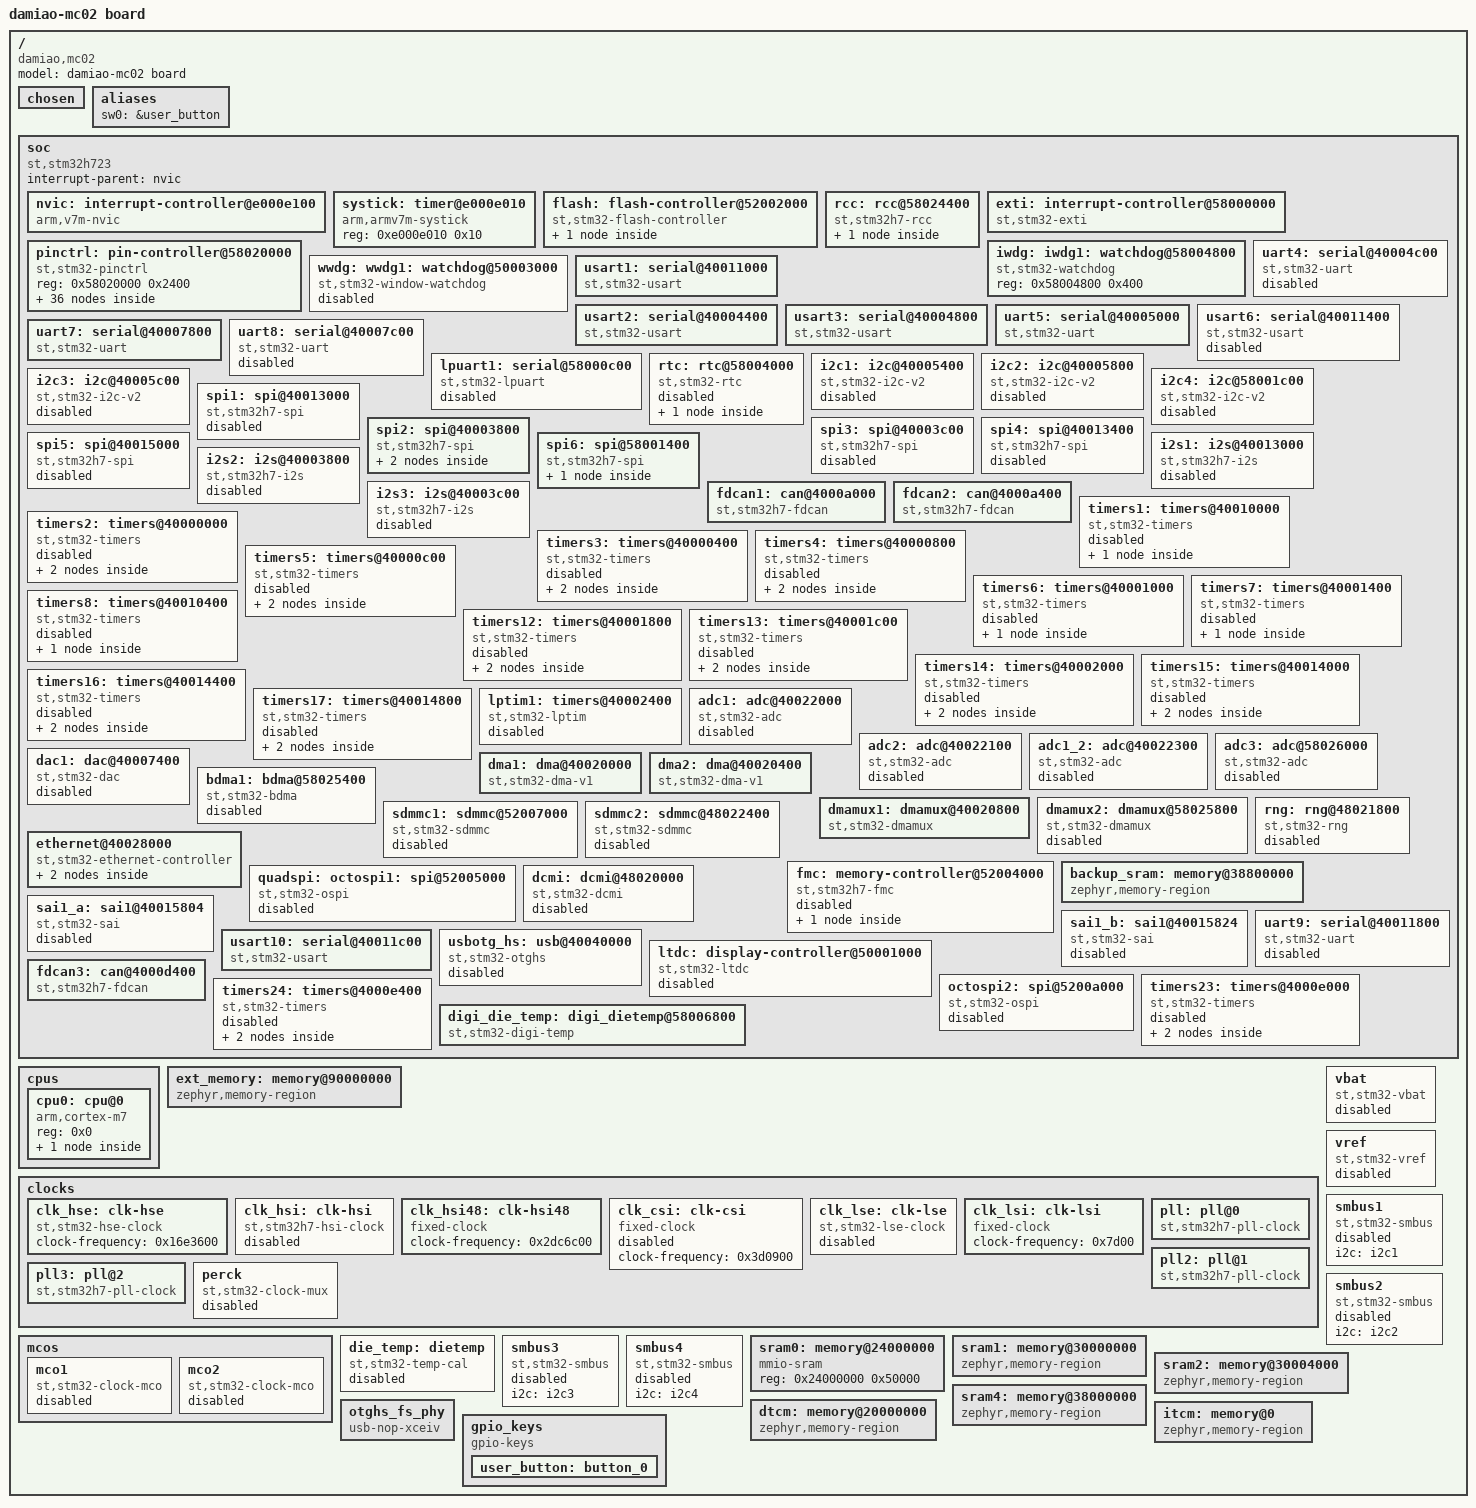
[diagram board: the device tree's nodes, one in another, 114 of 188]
/dts-v1/;

/* node '/' defined in Engineer-sdk/zephyr/dts/common/skeleton.dtsi:9 */
/ {
	#address-cells = < 0x1 >;    /* in Engineer-sdk/zephyr/dts/common/skeleton.dtsi:10 */
	#size-cells = < 0x1 >;       /* in Engineer-sdk/zephyr/dts/common/skeleton.dtsi:11 */
	model = "damiao-mc02 board"; /* in Engineer-manifest/boards/damiao/mc02/damiao_mc02.dts:24 */
	compatible = "damiao,mc02",
	             "st,stm32h723"; /* in Engineer-manifest/boards/damiao/mc02/damiao_mc02.dts:25 */

	/* node '/chosen' defined in Engineer-sdk/zephyr/dts/common/skeleton.dtsi:12 */
	chosen {
		zephyr,entropy = &rng;            /* in Engineer-sdk/zephyr/dts/arm/st/h7/stm32h7.dtsi:28 */
		zephyr,flash-controller = &flash; /* in Engineer-sdk/zephyr/dts/arm/st/h7/stm32h7.dtsi:29 */
		zephyr,dtcm = &dtcm;              /* in Engineer-manifest/boards/damiao/mc02/damiao_mc02.dts:28 */
		zephyr,sram = &sram0;             /* in Engineer-manifest/boards/damiao/mc02/damiao_mc02.dts:29 */
		zephyr,itcm = &itcm;              /* in Engineer-manifest/boards/damiao/mc02/damiao_mc02.dts:30 */
		zephyr,flash = &flash0;           /* in Engineer-manifest/boards/damiao/mc02/damiao_mc02.dts:31 */
	};

	/* node '/aliases' defined in Engineer-sdk/zephyr/dts/common/skeleton.dtsi:13 */
	aliases {
		sw0 = &user_button; /* in Engineer-manifest/boards/damiao/mc02/damiao_mc02.dts:44 */
	};

	/* node '/soc' defined in Engineer-sdk/zephyr/dts/arm/armv7-m.dtsi:6 */
	soc {
		#address-cells = < 0x1 >;     /* in Engineer-sdk/zephyr/dts/arm/armv7-m.dtsi:7 */
		#size-cells = < 0x1 >;        /* in Engineer-sdk/zephyr/dts/arm/armv7-m.dtsi:8 */
		interrupt-parent = < &nvic >; /* in Engineer-sdk/zephyr/dts/arm/armv7-m.dtsi:10 */
		ranges;                       /* in Engineer-sdk/zephyr/dts/arm/armv7-m.dtsi:11 */
		compatible = "st,stm32h723",
		             "st,stm32h7",
		             "simple-bus";    /* in Engineer-sdk/zephyr/dts/arm/st/h7/stm32h723.dtsi:15 */

		/* node '/soc/interrupt-controller@e000e100' defined in Engineer-sdk/zephyr/dts/arm/armv7-m.dtsi:13 */
		nvic: interrupt-controller@e000e100 {
			#address-cells = < 0x1 >;            /* in Engineer-sdk/zephyr/dts/arm/armv7-m.dtsi:14 */
			compatible = "arm,v7m-nvic";         /* in Engineer-sdk/zephyr/dts/arm/armv7-m.dtsi:15 */
			reg = < 0xe000e100 0xc00 >;          /* in Engineer-sdk/zephyr/dts/arm/armv7-m.dtsi:16 */
			interrupt-controller;                /* in Engineer-sdk/zephyr/dts/arm/armv7-m.dtsi:17 */
			#interrupt-cells = < 0x2 >;          /* in Engineer-sdk/zephyr/dts/arm/armv7-m.dtsi:18 */
			arm,num-irq-priority-bits = < 0x4 >; /* in Engineer-sdk/zephyr/dts/arm/st/h7/stm32h7.dtsi:1196 */
			phandle = < 0x1 >;                   /* in Engineer-sdk/zephyr/dts/arm/armv7-m.dtsi:10 */
		};

		/* node '/soc/timer@e000e010' defined in Engineer-sdk/zephyr/dts/arm/armv7-m.dtsi:21 */
		systick: timer@e000e010 {
			compatible = "arm,armv7m-systick"; /* in Engineer-sdk/zephyr/dts/arm/armv7-m.dtsi:22 */
			reg = < 0xe000e010 0x10 >;         /* in Engineer-sdk/zephyr/dts/arm/armv7-m.dtsi:23 */
		};

		/* node '/soc/flash-controller@52002000' defined in Engineer-sdk/zephyr/dts/arm/st/h7/stm32h7.dtsi:145 */
		flash: flash-controller@52002000 {
			compatible = "st,stm32-flash-controller",
			             "st,stm32h7-flash-controller"; /* in Engineer-sdk/zephyr/dts/arm/st/h7/stm32h7.dtsi:146 */
			reg = < 0x52002000 0x400 >;                 /* in Engineer-sdk/zephyr/dts/arm/st/h7/stm32h7.dtsi:147 */
			interrupts = < 0x4 0x0 >;                   /* in Engineer-sdk/zephyr/dts/arm/st/h7/stm32h7.dtsi:148 */
			#address-cells = < 0x1 >;                   /* in Engineer-sdk/zephyr/dts/arm/st/h7/stm32h7.dtsi:150 */
			#size-cells = < 0x1 >;                      /* in Engineer-sdk/zephyr/dts/arm/st/h7/stm32h7.dtsi:151 */

			/* node '/soc/flash-controller@52002000/flash@8000000' defined in Engineer-sdk/zephyr/dts/arm/st/h7/stm32h723.dtsi:18 */
			flash0: flash@8000000 {
				compatible = "st,stm32-nv-flash",
				             "soc-nv-flash";      /* in Engineer-sdk/zephyr/dts/arm/st/h7/stm32h723.dtsi:19 */
				write-block-size = < 0x20 >;      /* in Engineer-sdk/zephyr/dts/arm/st/h7/stm32h723.dtsi:20 */
				erase-block-size = < 0x20000 >;   /* in Engineer-sdk/zephyr/dts/arm/st/h7/stm32h723.dtsi:21 */
				max-erase-time = < 0xfa0 >;       /* in Engineer-sdk/zephyr/dts/arm/st/h7/stm32h723.dtsi:23 */
				reg = < 0x8000000 0x100000 >;     /* in Engineer-sdk/zephyr/dts/arm/st/h7/stm32h723Xg.dtsi:14 */
			};
		};

		/* node '/soc/rcc@58024400' defined in Engineer-sdk/zephyr/dts/arm/st/h7/stm32h7.dtsi:154 */
		rcc: rcc@58024400 {
			compatible = "st,stm32h7-rcc";    /* in Engineer-sdk/zephyr/dts/arm/st/h7/stm32h7.dtsi:155 */
			#clock-cells = < 0x2 >;           /* in Engineer-sdk/zephyr/dts/arm/st/h7/stm32h7.dtsi:156 */
			reg = < 0x58024400 0x400 >;       /* in Engineer-sdk/zephyr/dts/arm/st/h7/stm32h7.dtsi:157 */
			clocks = < &pll >;                /* in Engineer-manifest/boards/damiao/mc02/damiao_mc02.dts:96 */
			clock-frequency = < 0x20c85580 >; /* in Engineer-manifest/boards/damiao/mc02/damiao_mc02.dts:97 */
			d1cpre = < 0x1 >;                 /* in Engineer-manifest/boards/damiao/mc02/damiao_mc02.dts:98 */
			hpre = < 0x2 >;                   /* in Engineer-manifest/boards/damiao/mc02/damiao_mc02.dts:99 */
			d1ppre = < 0x2 >;                 /* in Engineer-manifest/boards/damiao/mc02/damiao_mc02.dts:100 */
			d2ppre1 = < 0x2 >;                /* in Engineer-manifest/boards/damiao/mc02/damiao_mc02.dts:101 */
			d2ppre2 = < 0x2 >;                /* in Engineer-manifest/boards/damiao/mc02/damiao_mc02.dts:102 */
			d3ppre = < 0x2 >;                 /* in Engineer-manifest/boards/damiao/mc02/damiao_mc02.dts:103 */
			phandle = < 0x3 >;                /* in Engineer-sdk/zephyr/dts/arm/st/h7/stm32h7.dtsi:171 */

			/* node '/soc/rcc@58024400/reset-controller' defined in Engineer-sdk/zephyr/dts/arm/st/h7/stm32h7.dtsi:159 */
			rctl: reset-controller {
				compatible = "st,stm32-rcc-rctl"; /* in Engineer-sdk/zephyr/dts/arm/st/h7/stm32h7.dtsi:160 */
				#reset-cells = < 0x1 >;           /* in Engineer-sdk/zephyr/dts/arm/st/h7/stm32h7.dtsi:161 */
				phandle = < 0x4 >;                /* in Engineer-sdk/zephyr/dts/arm/st/h7/stm32h7.dtsi:294 */
			};
		};

		/* node '/soc/interrupt-controller@58000000' defined in Engineer-sdk/zephyr/dts/arm/st/h7/stm32h7.dtsi:165 */
		exti: interrupt-controller@58000000 {
			compatible = "st,stm32-exti";  /* in Engineer-sdk/zephyr/dts/arm/st/h7/stm32h7.dtsi:166 */
			interrupt-controller;          /* in Engineer-sdk/zephyr/dts/arm/st/h7/stm32h7.dtsi:167 */
			#interrupt-cells = < 0x1 >;    /* in Engineer-sdk/zephyr/dts/arm/st/h7/stm32h7.dtsi:168 */
			#address-cells = < 0x1 >;      /* in Engineer-sdk/zephyr/dts/arm/st/h7/stm32h7.dtsi:169 */
			reg = < 0x58000000 0x400 >;    /* in Engineer-sdk/zephyr/dts/arm/st/h7/stm32h7.dtsi:170 */
			clocks = < &rcc 0xf4 0x2 >;    /* in Engineer-sdk/zephyr/dts/arm/st/h7/stm32h7.dtsi:171 */
			num-lines = < 0x60 >;          /* in Engineer-sdk/zephyr/dts/arm/st/h7/stm32h7.dtsi:172 */
			interrupts = < 0x6 0x0 >,
			             < 0x7 0x0 >,
			             < 0x8 0x0 >,
			             < 0x9 0x0 >,
			             < 0xa 0x0 >,
			             < 0x17 0x0 >,
			             < 0x28 0x0 >;     /* in Engineer-sdk/zephyr/dts/arm/st/h7/stm32h7.dtsi:173 */
			interrupt-names = "line0",
			                  "line1",
			                  "line2",
			                  "line3",
			                  "line4",
			                  "line5-9",
			                  "line10-15"; /* in Engineer-sdk/zephyr/dts/arm/st/h7/stm32h7.dtsi:175 */
			line-ranges = < 0x0 0x1 >,
			              < 0x1 0x1 >,
			              < 0x2 0x1 >,
			              < 0x3 0x1 >,
			              < 0x4 0x1 >,
			              < 0x5 0x5 >,
			              < 0xa 0x6 >;     /* in Engineer-sdk/zephyr/dts/arm/st/h7/stm32h7.dtsi:177 */
		};

		/* node '/soc/pin-controller@58020000' defined in Engineer-sdk/zephyr/dts/arm/st/h7/stm32h7.dtsi:181 */
		pinctrl: pin-controller@58020000 {
			compatible = "st,stm32-pinctrl"; /* in Engineer-sdk/zephyr/dts/arm/st/h7/stm32h7.dtsi:182 */
			#address-cells = < 0x1 >;        /* in Engineer-sdk/zephyr/dts/arm/st/h7/stm32h7.dtsi:183 */
			#size-cells = < 0x1 >;           /* in Engineer-sdk/zephyr/dts/arm/st/h7/stm32h7.dtsi:184 */
			reg = < 0x58020000 0x2400 >;     /* in Engineer-sdk/zephyr/dts/arm/st/h7/stm32h7.dtsi:185 */

			/* node '/soc/pin-controller@58020000/gpio@58020000' defined in Engineer-sdk/zephyr/dts/arm/st/h7/stm32h7.dtsi:187 */
			gpioa: gpio@58020000 {
				compatible = "st,stm32-gpio"; /* in Engineer-sdk/zephyr/dts/arm/st/h7/stm32h7.dtsi:188 */
				gpio-controller;              /* in Engineer-sdk/zephyr/dts/arm/st/h7/stm32h7.dtsi:189 */
				#gpio-cells = < 0x2 >;        /* in Engineer-sdk/zephyr/dts/arm/st/h7/stm32h7.dtsi:190 */
				reg = < 0x58020000 0x400 >;   /* in Engineer-sdk/zephyr/dts/arm/st/h7/stm32h7.dtsi:191 */
				clocks = < &rcc 0xe0 0x1 >;   /* in Engineer-sdk/zephyr/dts/arm/st/h7/stm32h7.dtsi:192 */
				phandle = < 0x2a >;           /* in Engineer-manifest/boards/damiao/mc02/damiao_mc02.dts:37 */
			};

			/* node '/soc/pin-controller@58020000/gpio@58020400' defined in Engineer-sdk/zephyr/dts/arm/st/h7/stm32h7.dtsi:195 */
			gpiob: gpio@58020400 {
				compatible = "st,stm32-gpio"; /* in Engineer-sdk/zephyr/dts/arm/st/h7/stm32h7.dtsi:196 */
				gpio-controller;              /* in Engineer-sdk/zephyr/dts/arm/st/h7/stm32h7.dtsi:197 */
				#gpio-cells = < 0x2 >;        /* in Engineer-sdk/zephyr/dts/arm/st/h7/stm32h7.dtsi:198 */
				reg = < 0x58020400 0x400 >;   /* in Engineer-sdk/zephyr/dts/arm/st/h7/stm32h7.dtsi:199 */
				clocks = < &rcc 0xe0 0x2 >;   /* in Engineer-sdk/zephyr/dts/arm/st/h7/stm32h7.dtsi:200 */
			};

			/* node '/soc/pin-controller@58020000/gpio@58020800' defined in Engineer-sdk/zephyr/dts/arm/st/h7/stm32h7.dtsi:203 */
			gpioc: gpio@58020800 {
				compatible = "st,stm32-gpio"; /* in Engineer-sdk/zephyr/dts/arm/st/h7/stm32h7.dtsi:204 */
				gpio-controller;              /* in Engineer-sdk/zephyr/dts/arm/st/h7/stm32h7.dtsi:205 */
				#gpio-cells = < 0x2 >;        /* in Engineer-sdk/zephyr/dts/arm/st/h7/stm32h7.dtsi:206 */
				reg = < 0x58020800 0x400 >;   /* in Engineer-sdk/zephyr/dts/arm/st/h7/stm32h7.dtsi:207 */
				clocks = < &rcc 0xe0 0x4 >;   /* in Engineer-sdk/zephyr/dts/arm/st/h7/stm32h7.dtsi:208 */
				phandle = < 0x15 >;           /* in Engineer-manifest/boards/damiao/mc02/damiao_mc02.dts:148 */
			};

			/* node '/soc/pin-controller@58020000/gpio@58020C00' defined in Engineer-sdk/zephyr/dts/arm/st/h7/stm32h7.dtsi:211 */
			gpiod: gpio@58020C00 {
				compatible = "st,stm32-gpio"; /* in Engineer-sdk/zephyr/dts/arm/st/h7/stm32h7.dtsi:212 */
				gpio-controller;              /* in Engineer-sdk/zephyr/dts/arm/st/h7/stm32h7.dtsi:213 */
				#gpio-cells = < 0x2 >;        /* in Engineer-sdk/zephyr/dts/arm/st/h7/stm32h7.dtsi:214 */
				reg = < 0x58020c00 0x400 >;   /* in Engineer-sdk/zephyr/dts/arm/st/h7/stm32h7.dtsi:215 */
				clocks = < &rcc 0xe0 0x8 >;   /* in Engineer-sdk/zephyr/dts/arm/st/h7/stm32h7.dtsi:216 */
			};

			/* node '/soc/pin-controller@58020000/gpio@58021000' defined in Engineer-sdk/zephyr/dts/arm/st/h7/stm32h7.dtsi:219 */
			gpioe: gpio@58021000 {
				compatible = "st,stm32-gpio"; /* in Engineer-sdk/zephyr/dts/arm/st/h7/stm32h7.dtsi:220 */
				gpio-controller;              /* in Engineer-sdk/zephyr/dts/arm/st/h7/stm32h7.dtsi:221 */
				#gpio-cells = < 0x2 >;        /* in Engineer-sdk/zephyr/dts/arm/st/h7/stm32h7.dtsi:222 */
				reg = < 0x58021000 0x400 >;   /* in Engineer-sdk/zephyr/dts/arm/st/h7/stm32h7.dtsi:223 */
				clocks = < &rcc 0xe0 0x10 >;  /* in Engineer-sdk/zephyr/dts/arm/st/h7/stm32h7.dtsi:224 */
				phandle = < 0x16 >;           /* in Engineer-manifest/boards/damiao/mc02/damiao_mc02.dts:160 */
			};

			/* node '/soc/pin-controller@58020000/gpio@58021400' defined in Engineer-sdk/zephyr/dts/arm/st/h7/stm32h7.dtsi:227 */
			gpiof: gpio@58021400 {
				compatible = "st,stm32-gpio"; /* in Engineer-sdk/zephyr/dts/arm/st/h7/stm32h7.dtsi:228 */
				gpio-controller;              /* in Engineer-sdk/zephyr/dts/arm/st/h7/stm32h7.dtsi:229 */
				#gpio-cells = < 0x2 >;        /* in Engineer-sdk/zephyr/dts/arm/st/h7/stm32h7.dtsi:230 */
				reg = < 0x58021400 0x400 >;   /* in Engineer-sdk/zephyr/dts/arm/st/h7/stm32h7.dtsi:231 */
				clocks = < &rcc 0xe0 0x20 >;  /* in Engineer-sdk/zephyr/dts/arm/st/h7/stm32h7.dtsi:232 */
			};

			/* node '/soc/pin-controller@58020000/gpio@58021800' defined in Engineer-sdk/zephyr/dts/arm/st/h7/stm32h7.dtsi:235 */
			gpiog: gpio@58021800 {
				compatible = "st,stm32-gpio"; /* in Engineer-sdk/zephyr/dts/arm/st/h7/stm32h7.dtsi:236 */
				gpio-controller;              /* in Engineer-sdk/zephyr/dts/arm/st/h7/stm32h7.dtsi:237 */
				#gpio-cells = < 0x2 >;        /* in Engineer-sdk/zephyr/dts/arm/st/h7/stm32h7.dtsi:238 */
				reg = < 0x58021800 0x400 >;   /* in Engineer-sdk/zephyr/dts/arm/st/h7/stm32h7.dtsi:239 */
				clocks = < &rcc 0xe0 0x40 >;  /* in Engineer-sdk/zephyr/dts/arm/st/h7/stm32h7.dtsi:240 */
			};

			/* node '/soc/pin-controller@58020000/gpio@58021C00' defined in Engineer-sdk/zephyr/dts/arm/st/h7/stm32h7.dtsi:243 */
			gpioh: gpio@58021C00 {
				compatible = "st,stm32-gpio"; /* in Engineer-sdk/zephyr/dts/arm/st/h7/stm32h7.dtsi:244 */
				gpio-controller;              /* in Engineer-sdk/zephyr/dts/arm/st/h7/stm32h7.dtsi:245 */
				#gpio-cells = < 0x2 >;        /* in Engineer-sdk/zephyr/dts/arm/st/h7/stm32h7.dtsi:246 */
				reg = < 0x58021c00 0x400 >;   /* in Engineer-sdk/zephyr/dts/arm/st/h7/stm32h7.dtsi:247 */
				clocks = < &rcc 0xe0 0x80 >;  /* in Engineer-sdk/zephyr/dts/arm/st/h7/stm32h7.dtsi:248 */
			};

			/* node '/soc/pin-controller@58020000/gpio@58022000' defined in Engineer-sdk/zephyr/dts/arm/st/h7/stm32h7.dtsi:251 */
			gpioi: gpio@58022000 {
				compatible = "st,stm32-gpio"; /* in Engineer-sdk/zephyr/dts/arm/st/h7/stm32h7.dtsi:252 */
				gpio-controller;              /* in Engineer-sdk/zephyr/dts/arm/st/h7/stm32h7.dtsi:253 */
				#gpio-cells = < 0x2 >;        /* in Engineer-sdk/zephyr/dts/arm/st/h7/stm32h7.dtsi:254 */
				reg = < 0x58022000 0x400 >;   /* in Engineer-sdk/zephyr/dts/arm/st/h7/stm32h7.dtsi:255 */
				clocks = < &rcc 0xe0 0x100 >; /* in Engineer-sdk/zephyr/dts/arm/st/h7/stm32h7.dtsi:256 */
			};

			/* node '/soc/pin-controller@58020000/gpio@58022400' defined in Engineer-sdk/zephyr/dts/arm/st/h7/stm32h7.dtsi:259 */
			gpioj: gpio@58022400 {
				compatible = "st,stm32-gpio"; /* in Engineer-sdk/zephyr/dts/arm/st/h7/stm32h7.dtsi:260 */
				gpio-controller;              /* in Engineer-sdk/zephyr/dts/arm/st/h7/stm32h7.dtsi:261 */
				#gpio-cells = < 0x2 >;        /* in Engineer-sdk/zephyr/dts/arm/st/h7/stm32h7.dtsi:262 */
				reg = < 0x58022400 0x400 >;   /* in Engineer-sdk/zephyr/dts/arm/st/h7/stm32h7.dtsi:263 */
				clocks = < &rcc 0xe0 0x200 >; /* in Engineer-sdk/zephyr/dts/arm/st/h7/stm32h7.dtsi:264 */
			};

			/* node '/soc/pin-controller@58020000/gpio@58022800' defined in Engineer-sdk/zephyr/dts/arm/st/h7/stm32h7.dtsi:267 */
			gpiok: gpio@58022800 {
				compatible = "st,stm32-gpio"; /* in Engineer-sdk/zephyr/dts/arm/st/h7/stm32h7.dtsi:268 */
				gpio-controller;              /* in Engineer-sdk/zephyr/dts/arm/st/h7/stm32h7.dtsi:269 */
				#gpio-cells = < 0x2 >;        /* in Engineer-sdk/zephyr/dts/arm/st/h7/stm32h7.dtsi:270 */
				reg = < 0x58022800 0x400 >;   /* in Engineer-sdk/zephyr/dts/arm/st/h7/stm32h7.dtsi:271 */
				clocks = < &rcc 0xe0 0x400 >; /* in Engineer-sdk/zephyr/dts/arm/st/h7/stm32h7.dtsi:272 */
			};

			/* node '/soc/pin-controller@58020000/fdcan1_rx_pd0' defined in Engineer-sdk/modules/hal/stm32/dts/st/h7/stm32h723vgtx-pinctrl.dtsi:1060 */
			fdcan1_rx_pd0: fdcan1_rx_pd0 {
				pinmux = < 0x609 >; /* in Engineer-sdk/modules/hal/stm32/dts/st/h7/stm32h723vgtx-pinctrl.dtsi:1061 */
				phandle = < 0x1a >; /* in Engineer-manifest/boards/damiao/mc02/damiao_mc02.dts:320 */
			};

			/* node '/soc/pin-controller@58020000/fdcan2_rx_pb5' defined in Engineer-sdk/modules/hal/stm32/dts/st/h7/stm32h723vgtx-pinctrl.dtsi:1064 */
			fdcan2_rx_pb5: fdcan2_rx_pb5 {
				pinmux = < 0x2a9 >; /* in Engineer-sdk/modules/hal/stm32/dts/st/h7/stm32h723vgtx-pinctrl.dtsi:1065 */
				phandle = < 0x1c >; /* in Engineer-manifest/boards/damiao/mc02/damiao_mc02.dts:329 */
			};

			/* node '/soc/pin-controller@58020000/fdcan3_rx_pd12' defined in Engineer-sdk/modules/hal/stm32/dts/st/h7/stm32h723vgtx-pinctrl.dtsi:1072 */
			fdcan3_rx_pd12: fdcan3_rx_pd12 {
				pinmux = < 0x785 >; /* in Engineer-sdk/modules/hal/stm32/dts/st/h7/stm32h723vgtx-pinctrl.dtsi:1073 */
				phandle = < 0x22 >; /* in Engineer-manifest/boards/damiao/mc02/damiao_mc02.dts:338 */
			};

			/* node '/soc/pin-controller@58020000/fdcan1_tx_pd1' defined in Engineer-sdk/modules/hal/stm32/dts/st/h7/stm32h723vgtx-pinctrl.dtsi:1086 */
			fdcan1_tx_pd1: fdcan1_tx_pd1 {
				pinmux = < 0x629 >; /* in Engineer-sdk/modules/hal/stm32/dts/st/h7/stm32h723vgtx-pinctrl.dtsi:1087 */
				phandle = < 0x1b >; /* in Engineer-manifest/boards/damiao/mc02/damiao_mc02.dts:320 */
			};

			/* node '/soc/pin-controller@58020000/fdcan2_tx_pb6' defined in Engineer-sdk/modules/hal/stm32/dts/st/h7/stm32h723vgtx-pinctrl.dtsi:1090 */
			fdcan2_tx_pb6: fdcan2_tx_pb6 {
				pinmux = < 0x2c9 >; /* in Engineer-sdk/modules/hal/stm32/dts/st/h7/stm32h723vgtx-pinctrl.dtsi:1091 */
				phandle = < 0x1d >; /* in Engineer-manifest/boards/damiao/mc02/damiao_mc02.dts:329 */
			};

			/* node '/soc/pin-controller@58020000/fdcan3_tx_pd13' defined in Engineer-sdk/modules/hal/stm32/dts/st/h7/stm32h723vgtx-pinctrl.dtsi:1098 */
			fdcan3_tx_pd13: fdcan3_tx_pd13 {
				pinmux = < 0x7a5 >; /* in Engineer-sdk/modules/hal/stm32/dts/st/h7/stm32h723vgtx-pinctrl.dtsi:1099 */
				phandle = < 0x23 >; /* in Engineer-manifest/boards/damiao/mc02/damiao_mc02.dts:338 */
			};

			/* node '/soc/pin-controller@58020000/spi2_miso_pc2_c' defined in Engineer-sdk/modules/hal/stm32/dts/st/h7/stm32h723vgtx-pinctrl.dtsi:2577 */
			spi2_miso_pc2_c: spi2_miso_pc2_c {
				pinmux = < 0x445 >; /* in Engineer-sdk/modules/hal/stm32/dts/st/h7/stm32h723vgtx-pinctrl.dtsi:2578 */
				bias-pull-down;     /* in Engineer-sdk/modules/hal/stm32/dts/st/h7/stm32h723vgtx-pinctrl.dtsi:2579 */
				phandle = < 0x13 >; /* in Engineer-manifest/boards/damiao/mc02/damiao_mc02.dts:146 */
			};

			/* node '/soc/pin-controller@58020000/spi2_mosi_pc1' defined in Engineer-sdk/modules/hal/stm32/dts/st/h7/stm32h723vgtx-pinctrl.dtsi:2634 */
			spi2_mosi_pc1: spi2_mosi_pc1 {
				pinmux = < 0x425 >; /* in Engineer-sdk/modules/hal/stm32/dts/st/h7/stm32h723vgtx-pinctrl.dtsi:2635 */
				bias-pull-down;     /* in Engineer-sdk/modules/hal/stm32/dts/st/h7/stm32h723vgtx-pinctrl.dtsi:2636 */
				phandle = < 0x14 >; /* in Engineer-manifest/boards/damiao/mc02/damiao_mc02.dts:146 */
			};

			/* node '/soc/pin-controller@58020000/spi6_mosi_pa7' defined in Engineer-sdk/modules/hal/stm32/dts/st/h7/stm32h723vgtx-pinctrl.dtsi:2674 */
			spi6_mosi_pa7: spi6_mosi_pa7 {
				pinmux = < 0xe8 >;  /* in Engineer-sdk/modules/hal/stm32/dts/st/h7/stm32h723vgtx-pinctrl.dtsi:2675 */
				bias-pull-down;     /* in Engineer-sdk/modules/hal/stm32/dts/st/h7/stm32h723vgtx-pinctrl.dtsi:2676 */
				phandle = < 0x19 >; /* in Engineer-manifest/boards/damiao/mc02/damiao_mc02.dts:190 */
			};

			/* node '/soc/pin-controller@58020000/spi2_sck_pb13' defined in Engineer-sdk/modules/hal/stm32/dts/st/h7/stm32h723vgtx-pinctrl.dtsi:2783 */
			spi2_sck_pb13: spi2_sck_pb13 {
				pinmux = < 0x3a5 >;            /* in Engineer-sdk/modules/hal/stm32/dts/st/h7/stm32h723vgtx-pinctrl.dtsi:2784 */
				bias-pull-down;                /* in Engineer-sdk/modules/hal/stm32/dts/st/h7/stm32h723vgtx-pinctrl.dtsi:2785 */
				slew-rate = "very-high-speed"; /* in Engineer-sdk/modules/hal/stm32/dts/st/h7/stm32h723vgtx-pinctrl.dtsi:2786 */
				phandle = < 0x12 >;            /* in Engineer-manifest/boards/damiao/mc02/damiao_mc02.dts:146 */
			};

			/* node '/soc/pin-controller@58020000/spi6_sck_pa5' defined in Engineer-sdk/modules/hal/stm32/dts/st/h7/stm32h723vgtx-pinctrl.dtsi:2819 */
			spi6_sck_pa5: spi6_sck_pa5 {
				pinmux = < 0xa8 >;             /* in Engineer-sdk/modules/hal/stm32/dts/st/h7/stm32h723vgtx-pinctrl.dtsi:2820 */
				bias-pull-down;                /* in Engineer-sdk/modules/hal/stm32/dts/st/h7/stm32h723vgtx-pinctrl.dtsi:2821 */
				slew-rate = "very-high-speed"; /* in Engineer-sdk/modules/hal/stm32/dts/st/h7/stm32h723vgtx-pinctrl.dtsi:2822 */
				phandle = < 0x18 >;            /* in Engineer-manifest/boards/damiao/mc02/damiao_mc02.dts:190 */
			};

			/* node '/soc/pin-controller@58020000/usart2_de_pd4' defined in Engineer-sdk/modules/hal/stm32/dts/st/h7/stm32h723vgtx-pinctrl.dtsi:3260 */
			usart2_de_pd4: usart2_de_pd4 {
				pinmux = < 0x687 >; /* in Engineer-sdk/modules/hal/stm32/dts/st/h7/stm32h723vgtx-pinctrl.dtsi:3261 */
				drive-push-pull;    /* in Engineer-sdk/modules/hal/stm32/dts/st/h7/stm32h723vgtx-pinctrl.dtsi:3262 */
				phandle = < 0x8 >;  /* in Engineer-manifest/boards/damiao/mc02/damiao_mc02.dts:266 */
			};

			/* node '/soc/pin-controller@58020000/usart3_de_pb14' defined in Engineer-sdk/modules/hal/stm32/dts/st/h7/stm32h723vgtx-pinctrl.dtsi:3265 */
			usart3_de_pb14: usart3_de_pb14 {
				pinmux = < 0x3c7 >; /* in Engineer-sdk/modules/hal/stm32/dts/st/h7/stm32h723vgtx-pinctrl.dtsi:3266 */
				drive-push-pull;    /* in Engineer-sdk/modules/hal/stm32/dts/st/h7/stm32h723vgtx-pinctrl.dtsi:3267 */
				phandle = < 0xb >;  /* in Engineer-manifest/boards/damiao/mc02/damiao_mc02.dts:276 */
			};

			/* node '/soc/pin-controller@58020000/usart10_rx_pe2' defined in Engineer-sdk/modules/hal/stm32/dts/st/h7/stm32h723vgtx-pinctrl.dtsi:3369 */
			usart10_rx_pe2: usart10_rx_pe2 {
				pinmux = < 0x844 >; /* in Engineer-sdk/modules/hal/stm32/dts/st/h7/stm32h723vgtx-pinctrl.dtsi:3370 */
				phandle = < 0x20 >; /* in Engineer-manifest/boards/damiao/mc02/damiao_mc02.dts:245 */
			};

			/* node '/soc/pin-controller@58020000/usart1_rx_pa10' defined in Engineer-sdk/modules/hal/stm32/dts/st/h7/stm32h723vgtx-pinctrl.dtsi:3377 */
			usart1_rx_pa10: usart1_rx_pa10 {
				pinmux = < 0x147 >; /* in Engineer-sdk/modules/hal/stm32/dts/st/h7/stm32h723vgtx-pinctrl.dtsi:3378 */
				phandle = < 0x6 >;  /* in Engineer-manifest/boards/damiao/mc02/damiao_mc02.dts:220 */
			};

			/* node '/soc/pin-controller@58020000/usart2_rx_pd6' defined in Engineer-sdk/modules/hal/stm32/dts/st/h7/stm32h723vgtx-pinctrl.dtsi:3397 */
			usart2_rx_pd6: usart2_rx_pd6 {
				pinmux = < 0x6c7 >; /* in Engineer-sdk/modules/hal/stm32/dts/st/h7/stm32h723vgtx-pinctrl.dtsi:3398 */
				phandle = < 0x9 >;  /* in Engineer-manifest/boards/damiao/mc02/damiao_mc02.dts:266 */
			};

			/* node '/soc/pin-controller@58020000/usart3_rx_pd9' defined in Engineer-sdk/modules/hal/stm32/dts/st/h7/stm32h723vgtx-pinctrl.dtsi:3409 */
			usart3_rx_pd9: usart3_rx_pd9 {
				pinmux = < 0x727 >; /* in Engineer-sdk/modules/hal/stm32/dts/st/h7/stm32h723vgtx-pinctrl.dtsi:3410 */
				phandle = < 0xc >;  /* in Engineer-manifest/boards/damiao/mc02/damiao_mc02.dts:276 */
			};

			/* node '/soc/pin-controller@58020000/uart5_rx_pd2' defined in Engineer-sdk/modules/hal/stm32/dts/st/h7/stm32h723vgtx-pinctrl.dtsi:3441 */
			uart5_rx_pd2: uart5_rx_pd2 {
				pinmux = < 0x648 >; /* in Engineer-sdk/modules/hal/stm32/dts/st/h7/stm32h723vgtx-pinctrl.dtsi:3442 */
				phandle = < 0xe >;  /* in Engineer-manifest/boards/damiao/mc02/damiao_mc02.dts:288 */
			};

			/* node '/soc/pin-controller@58020000/uart7_rx_pe7' defined in Engineer-sdk/modules/hal/stm32/dts/st/h7/stm32h723vgtx-pinctrl.dtsi:3457 */
			uart7_rx_pe7: uart7_rx_pe7 {
				pinmux = < 0x8e7 >; /* in Engineer-sdk/modules/hal/stm32/dts/st/h7/stm32h723vgtx-pinctrl.dtsi:3458 */
				phandle = < 0x11 >; /* in Engineer-manifest/boards/damiao/mc02/damiao_mc02.dts:234 */
			};

			/* node '/soc/pin-controller@58020000/usart10_tx_pe3' defined in Engineer-sdk/modules/hal/stm32/dts/st/h7/stm32h723vgtx-pinctrl.dtsi:3471 */
			usart10_tx_pe3: usart10_tx_pe3 {
				pinmux = < 0x86b >; /* in Engineer-sdk/modules/hal/stm32/dts/st/h7/stm32h723vgtx-pinctrl.dtsi:3472 */
				bias-pull-up;       /* in Engineer-sdk/modules/hal/stm32/dts/st/h7/stm32h723vgtx-pinctrl.dtsi:3473 */
				phandle = < 0x1f >; /* in Engineer-manifest/boards/damiao/mc02/damiao_mc02.dts:245 */
			};

			/* node '/soc/pin-controller@58020000/usart1_tx_pa9' defined in Engineer-sdk/modules/hal/stm32/dts/st/h7/stm32h723vgtx-pinctrl.dtsi:3481 */
			usart1_tx_pa9: usart1_tx_pa9 {
				pinmux = < 0x127 >; /* in Engineer-sdk/modules/hal/stm32/dts/st/h7/stm32h723vgtx-pinctrl.dtsi:3482 */
				bias-pull-up;       /* in Engineer-sdk/modules/hal/stm32/dts/st/h7/stm32h723vgtx-pinctrl.dtsi:3483 */
				phandle = < 0x5 >;  /* in Engineer-manifest/boards/damiao/mc02/damiao_mc02.dts:220 */
			};

			/* node '/soc/pin-controller@58020000/usart2_tx_pd5' defined in Engineer-sdk/modules/hal/stm32/dts/st/h7/stm32h723vgtx-pinctrl.dtsi:3506 */
			usart2_tx_pd5: usart2_tx_pd5 {
				pinmux = < 0x6a7 >; /* in Engineer-sdk/modules/hal/stm32/dts/st/h7/stm32h723vgtx-pinctrl.dtsi:3507 */
				bias-pull-up;       /* in Engineer-sdk/modules/hal/stm32/dts/st/h7/stm32h723vgtx-pinctrl.dtsi:3508 */
				phandle = < 0xa >;  /* in Engineer-manifest/boards/damiao/mc02/damiao_mc02.dts:266 */
			};

			/* node '/soc/pin-controller@58020000/usart3_tx_pd8' defined in Engineer-sdk/modules/hal/stm32/dts/st/h7/stm32h723vgtx-pinctrl.dtsi:3521 */
			usart3_tx_pd8: usart3_tx_pd8 {
				pinmux = < 0x707 >; /* in Engineer-sdk/modules/hal/stm32/dts/st/h7/stm32h723vgtx-pinctrl.dtsi:3522 */
				bias-pull-up;       /* in Engineer-sdk/modules/hal/stm32/dts/st/h7/stm32h723vgtx-pinctrl.dtsi:3523 */
				phandle = < 0xd >;  /* in Engineer-manifest/boards/damiao/mc02/damiao_mc02.dts:276 */
			};

			/* node '/soc/pin-controller@58020000/uart5_tx_pc12' defined in Engineer-sdk/modules/hal/stm32/dts/st/h7/stm32h723vgtx-pinctrl.dtsi:3561 */
			uart5_tx_pc12: uart5_tx_pc12 {
				pinmux = < 0x588 >; /* in Engineer-sdk/modules/hal/stm32/dts/st/h7/stm32h723vgtx-pinctrl.dtsi:3562 */
				bias-pull-up;       /* in Engineer-sdk/modules/hal/stm32/dts/st/h7/stm32h723vgtx-pinctrl.dtsi:3563 */
				phandle = < 0xf >;  /* in Engineer-manifest/boards/damiao/mc02/damiao_mc02.dts:288 */
			};

			/* node '/soc/pin-controller@58020000/uart7_tx_pe8' defined in Engineer-sdk/modules/hal/stm32/dts/st/h7/stm32h723vgtx-pinctrl.dtsi:3581 */
			uart7_tx_pe8: uart7_tx_pe8 {
				pinmux = < 0x907 >; /* in Engineer-sdk/modules/hal/stm32/dts/st/h7/stm32h723vgtx-pinctrl.dtsi:3582 */
				bias-pull-up;       /* in Engineer-sdk/modules/hal/stm32/dts/st/h7/stm32h723vgtx-pinctrl.dtsi:3583 */
				phandle = < 0x10 >; /* in Engineer-manifest/boards/damiao/mc02/damiao_mc02.dts:234 */
			};
		};

		/* node '/soc/watchdog@58004800' defined in Engineer-sdk/zephyr/dts/arm/st/h7/stm32h7.dtsi:276 */
		iwdg: iwdg1: watchdog@58004800 {
			compatible = "st,stm32-watchdog"; /* in Engineer-sdk/zephyr/dts/arm/st/h7/stm32h7.dtsi:277 */
			reg = < 0x58004800 0x400 >;       /* in Engineer-sdk/zephyr/dts/arm/st/h7/stm32h7.dtsi:278 */
			status = "okay";                  /* in Engineer-manifest/boards/damiao/mc02/damiao_mc02.dts:107 */
		};

		/* node '/soc/watchdog@50003000' defined in Engineer-sdk/zephyr/dts/arm/st/h7/stm32h7.dtsi:282 */
		wwdg: wwdg1: watchdog@50003000 {
			compatible = "st,stm32-window-watchdog"; /* in Engineer-sdk/zephyr/dts/arm/st/h7/stm32h7.dtsi:283 */
			reg = < 0x50003000 0x1000 >;             /* in Engineer-sdk/zephyr/dts/arm/st/h7/stm32h7.dtsi:284 */
			clocks = < &rcc 0xe4 0x40 >;             /* in Engineer-sdk/zephyr/dts/arm/st/h7/stm32h7.dtsi:285 */
			interrupts = < 0x0 0x7 >;                /* in Engineer-sdk/zephyr/dts/arm/st/h7/stm32h7.dtsi:286 */
			status = "disabled";                     /* in Engineer-sdk/zephyr/dts/arm/st/h7/stm32h7.dtsi:287 */
		};

		/* node '/soc/serial@40011000' defined in Engineer-sdk/zephyr/dts/arm/st/h7/stm32h7.dtsi:290 */
		usart1: serial@40011000 {
			compatible = "st,stm32-usart",
			             "st,stm32-uart";                   /* in Engineer-sdk/zephyr/dts/arm/st/h7/stm32h7.dtsi:291 */
			reg = < 0x40011000 0x400 >;                     /* in Engineer-sdk/zephyr/dts/arm/st/h7/stm32h7.dtsi:292 */
			clocks = < &rcc 0xf0 0x10 >;                    /* in Engineer-sdk/zephyr/dts/arm/st/h7/stm32h7.dtsi:293 */
			resets = < &rctl 0x1304 >;                      /* in Engineer-sdk/zephyr/dts/arm/st/h7/stm32h7.dtsi:294 */
			interrupts = < 0x25 0x0 >;                      /* in Engineer-sdk/zephyr/dts/arm/st/h7/stm32h7.dtsi:295 */
			status = "okay";                                /* in Engineer-manifest/boards/damiao/mc02/damiao_mc02.dts:215 */
			current-speed = < 0x1c200 >;                    /* in Engineer-manifest/boards/damiao/mc02/damiao_mc02.dts:216 */
			stop-bits = "1";                                /* in Engineer-manifest/boards/damiao/mc02/damiao_mc02.dts:217 */
			data-bits = < 0x8 >;                            /* in Engineer-manifest/boards/damiao/mc02/damiao_mc02.dts:218 */
			parity = "none";                                /* in Engineer-manifest/boards/damiao/mc02/damiao_mc02.dts:219 */
			pinctrl-0 = < &usart1_tx_pa9 &usart1_rx_pa10 >; /* in Engineer-manifest/boards/damiao/mc02/damiao_mc02.dts:220 */
			pinctrl-names = "default";                      /* in Engineer-manifest/boards/damiao/mc02/damiao_mc02.dts:221 */
			dmas = < &dmamux1 0x9 0x2a 0x440 >,
			       < &dmamux1 0x8 0x29 0x480 >;             /* in Engineer-manifest/boards/damiao/mc02/damiao_mc02.dts:222 */
			dma-names = "usart1-tx",
			            "usart1-rx";                        /* in Engineer-manifest/boards/damiao/mc02/damiao_mc02.dts:224 */
			fifo-enable;                                    /* in Engineer-manifest/boards/damiao/mc02/damiao_mc02.dts:225 */
		};

		/* node '/soc/serial@40004400' defined in Engineer-sdk/zephyr/dts/arm/st/h7/stm32h7.dtsi:298 */
		usart2: serial@40004400 {
			compatible = "st,stm32-usart",
			             "st,stm32-uart";                                 /* in Engineer-sdk/zephyr/dts/arm/st/h7/stm32h7.dtsi:299 */
			reg = < 0x40004400 0x400 >;                                   /* in Engineer-sdk/zephyr/dts/arm/st/h7/stm32h7.dtsi:300 */
			clocks = < &rcc 0xe8 0x20000 >;                               /* in Engineer-sdk/zephyr/dts/arm/st/h7/stm32h7.dtsi:301 */
			resets = < &rctl 0x1211 >;                                    /* in Engineer-sdk/zephyr/dts/arm/st/h7/stm32h7.dtsi:302 */
			interrupts = < 0x26 0x0 >;                                    /* in Engineer-sdk/zephyr/dts/arm/st/h7/stm32h7.dtsi:303 */
			status = "okay";                                              /* in Engineer-manifest/boards/damiao/mc02/damiao_mc02.dts:262 */
			current-speed = < 0x1c200 >;                                  /* in Engineer-manifest/boards/damiao/mc02/damiao_mc02.dts:263 */
			stop-bits = "1";                                              /* in Engineer-manifest/boards/damiao/mc02/damiao_mc02.dts:264 */
			data-bits = < 0x8 >;                                          /* in Engineer-manifest/boards/damiao/mc02/damiao_mc02.dts:265 */
			pinctrl-0 = < &usart2_de_pd4 &usart2_rx_pd6 &usart2_tx_pd5 >; /* in Engineer-manifest/boards/damiao/mc02/damiao_mc02.dts:266 */
			pinctrl-names = "default";                                    /* in Engineer-manifest/boards/damiao/mc02/damiao_mc02.dts:267 */
			de-enable;                                                    /* in Engineer-manifest/boards/damiao/mc02/damiao_mc02.dts:268 */
		};

		/* node '/soc/serial@40004800' defined in Engineer-sdk/zephyr/dts/arm/st/h7/stm32h7.dtsi:306 */
		usart3: serial@40004800 {
			compatible = "st,stm32-usart",
			             "st,stm32-uart";                                  /* in Engineer-sdk/zephyr/dts/arm/st/h7/stm32h7.dtsi:307 */
			reg = < 0x40004800 0x400 >;                                    /* in Engineer-sdk/zephyr/dts/arm/st/h7/stm32h7.dtsi:308 */
			clocks = < &rcc 0xe8 0x40000 >;                                /* in Engineer-sdk/zephyr/dts/arm/st/h7/stm32h7.dtsi:309 */
			resets = < &rctl 0x1212 >;                                     /* in Engineer-sdk/zephyr/dts/arm/st/h7/stm32h7.dtsi:310 */
			interrupts = < 0x27 0x0 >;                                     /* in Engineer-sdk/zephyr/dts/arm/st/h7/stm32h7.dtsi:311 */
			status = "okay";                                               /* in Engineer-manifest/boards/damiao/mc02/damiao_mc02.dts:272 */
			current-speed = < 0x1c200 >;                                   /* in Engineer-manifest/boards/damiao/mc02/damiao_mc02.dts:273 */
			stop-bits = "1";                                               /* in Engineer-manifest/boards/damiao/mc02/damiao_mc02.dts:274 */
			data-bits = < 0x8 >;                                           /* in Engineer-manifest/boards/damiao/mc02/damiao_mc02.dts:275 */
			pinctrl-0 = < &usart3_de_pb14 &usart3_rx_pd9 &usart3_tx_pd8 >; /* in Engineer-manifest/boards/damiao/mc02/damiao_mc02.dts:276 */
			pinctrl-names = "default";                                     /* in Engineer-manifest/boards/damiao/mc02/damiao_mc02.dts:277 */
			de-enable;                                                     /* in Engineer-manifest/boards/damiao/mc02/damiao_mc02.dts:278 */
		};

		/* node '/soc/serial@40004c00' defined in Engineer-sdk/zephyr/dts/arm/st/h7/stm32h7.dtsi:314 */
		uart4: serial@40004c00 {
			compatible = "st,stm32-uart";   /* in Engineer-sdk/zephyr/dts/arm/st/h7/stm32h7.dtsi:315 */
			reg = < 0x40004c00 0x400 >;     /* in Engineer-sdk/zephyr/dts/arm/st/h7/stm32h7.dtsi:316 */
			clocks = < &rcc 0xe8 0x80000 >; /* in Engineer-sdk/zephyr/dts/arm/st/h7/stm32h7.dtsi:317 */
			resets = < &rctl 0x1213 >;      /* in Engineer-sdk/zephyr/dts/arm/st/h7/stm32h7.dtsi:318 */
			interrupts = < 0x34 0x0 >;      /* in Engineer-sdk/zephyr/dts/arm/st/h7/stm32h7.dtsi:319 */
			status = "disabled";            /* in Engineer-sdk/zephyr/dts/arm/st/h7/stm32h7.dtsi:320 */
		};

		/* node '/soc/serial@40005000' defined in Engineer-sdk/zephyr/dts/arm/st/h7/stm32h7.dtsi:322 */
		uart5: serial@40005000 {
			compatible = "st,stm32-uart";                 /* in Engineer-sdk/zephyr/dts/arm/st/h7/stm32h7.dtsi:323 */
			reg = < 0x40005000 0x400 >;                   /* in Engineer-sdk/zephyr/dts/arm/st/h7/stm32h7.dtsi:324 */
			clocks = < &rcc 0xe8 0x100000 >;              /* in Engineer-sdk/zephyr/dts/arm/st/h7/stm32h7.dtsi:325 */
			resets = < &rctl 0x1214 >;                    /* in Engineer-sdk/zephyr/dts/arm/st/h7/stm32h7.dtsi:326 */
			interrupts = < 0x35 0x0 >;                    /* in Engineer-sdk/zephyr/dts/arm/st/h7/stm32h7.dtsi:327 */
			status = "okay";                              /* in Engineer-manifest/boards/damiao/mc02/damiao_mc02.dts:283 */
			current-speed = < 0x186a0 >;                  /* in Engineer-manifest/boards/damiao/mc02/damiao_mc02.dts:284 */
			stop-bits = "1";                              /* in Engineer-manifest/boards/damiao/mc02/damiao_mc02.dts:285 */
			data-bits = < 0x8 >;                          /* in Engineer-manifest/boards/damiao/mc02/damiao_mc02.dts:286 */
			parity = "even";                              /* in Engineer-manifest/boards/damiao/mc02/damiao_mc02.dts:287 */
			pinctrl-0 = < &uart5_rx_pd2 &uart5_tx_pc12 >; /* in Engineer-manifest/boards/damiao/mc02/damiao_mc02.dts:288 */
			pinctrl-names = "default";                    /* in Engineer-manifest/boards/damiao/mc02/damiao_mc02.dts:289 */
			fifo-enable;                                  /* in Engineer-manifest/boards/damiao/mc02/damiao_mc02.dts:290 */
		};

		/* node '/soc/serial@40011400' defined in Engineer-sdk/zephyr/dts/arm/st/h7/stm32h7.dtsi:330 */
		usart6: serial@40011400 {
			compatible = "st,stm32-usart",
			             "st,stm32-uart";  /* in Engineer-sdk/zephyr/dts/arm/st/h7/stm32h7.dtsi:331 */
			reg = < 0x40011400 0x400 >;    /* in Engineer-sdk/zephyr/dts/arm/st/h7/stm32h7.dtsi:332 */
			clocks = < &rcc 0xf0 0x20 >;   /* in Engineer-sdk/zephyr/dts/arm/st/h7/stm32h7.dtsi:333 */
			resets = < &rctl 0x1305 >;     /* in Engineer-sdk/zephyr/dts/arm/st/h7/stm32h7.dtsi:334 */
			interrupts = < 0x47 0x0 >;     /* in Engineer-sdk/zephyr/dts/arm/st/h7/stm32h7.dtsi:335 */
			status = "disabled";           /* in Engineer-sdk/zephyr/dts/arm/st/h7/stm32h7.dtsi:336 */
		};

		/* node '/soc/serial@40007800' defined in Engineer-sdk/zephyr/dts/arm/st/h7/stm32h7.dtsi:338 */
		uart7: serial@40007800 {
			compatible = "st,stm32-uart";                /* in Engineer-sdk/zephyr/dts/arm/st/h7/stm32h7.dtsi:339 */
			reg = < 0x40007800 0x400 >;                  /* in Engineer-sdk/zephyr/dts/arm/st/h7/stm32h7.dtsi:340 */
			clocks = < &rcc 0xe8 0x40000000 >;           /* in Engineer-sdk/zephyr/dts/arm/st/h7/stm32h7.dtsi:341 */
			resets = < &rctl 0x121e >;                   /* in Engineer-sdk/zephyr/dts/arm/st/h7/stm32h7.dtsi:342 */
			interrupts = < 0x52 0x0 >;                   /* in Engineer-sdk/zephyr/dts/arm/st/h7/stm32h7.dtsi:343 */
			status = "okay";                             /* in Engineer-manifest/boards/damiao/mc02/damiao_mc02.dts:229 */
			current-speed = < 0xe1000 >;                 /* in Engineer-manifest/boards/damiao/mc02/damiao_mc02.dts:230 */
			stop-bits = "1";                             /* in Engineer-manifest/boards/damiao/mc02/damiao_mc02.dts:231 */
			data-bits = < 0x8 >;                         /* in Engineer-manifest/boards/damiao/mc02/damiao_mc02.dts:232 */
			parity = "none";                             /* in Engineer-manifest/boards/damiao/mc02/damiao_mc02.dts:233 */
			pinctrl-0 = < &uart7_tx_pe8 &uart7_rx_pe7 >; /* in Engineer-manifest/boards/damiao/mc02/damiao_mc02.dts:234 */
			pinctrl-names = "default";                   /* in Engineer-manifest/boards/damiao/mc02/damiao_mc02.dts:235 */
			fifo-enable;                                 /* in Engineer-manifest/boards/damiao/mc02/damiao_mc02.dts:236 */
		};

		/* node '/soc/serial@40007c00' defined in Engineer-sdk/zephyr/dts/arm/st/h7/stm32h7.dtsi:346 */
		uart8: serial@40007c00 {
			compatible = "st,stm32-uart";      /* in Engineer-sdk/zephyr/dts/arm/st/h7/stm32h7.dtsi:347 */
			reg = < 0x40007c00 0x400 >;        /* in Engineer-sdk/zephyr/dts/arm/st/h7/stm32h7.dtsi:348 */
			clocks = < &rcc 0xe8 0x80000000 >; /* in Engineer-sdk/zephyr/dts/arm/st/h7/stm32h7.dtsi:349 */
			resets = < &rctl 0x121f >;         /* in Engineer-sdk/zephyr/dts/arm/st/h7/stm32h7.dtsi:350 */
			interrupts = < 0x53 0x0 >;         /* in Engineer-sdk/zephyr/dts/arm/st/h7/stm32h7.dtsi:351 */
			status = "disabled";               /* in Engineer-sdk/zephyr/dts/arm/st/h7/stm32h7.dtsi:352 */
		};

		/* node '/soc/serial@58000c00' defined in Engineer-sdk/zephyr/dts/arm/st/h7/stm32h7.dtsi:355 */
		lpuart1: serial@58000c00 {
			compatible = "st,stm32-lpuart",
			             "st,stm32-uart";   /* in Engineer-sdk/zephyr/dts/arm/st/h7/stm32h7.dtsi:356 */
			reg = < 0x58000c00 0x400 >;     /* in Engineer-sdk/zephyr/dts/arm/st/h7/stm32h7.dtsi:357 */
			clocks = < &rcc 0xf4 0x8 >;     /* in Engineer-sdk/zephyr/dts/arm/st/h7/stm32h7.dtsi:358 */
			resets = < &rctl 0x1383 >;      /* in Engineer-sdk/zephyr/dts/arm/st/h7/stm32h7.dtsi:359 */
			interrupts = < 0x8e 0x0 >;      /* in Engineer-sdk/zephyr/dts/arm/st/h7/stm32h7.dtsi:360 */
			status = "disabled";            /* in Engineer-sdk/zephyr/dts/arm/st/h7/stm32h7.dtsi:361 */
		};

		/* node '/soc/rtc@58004000' defined in Engineer-sdk/zephyr/dts/arm/st/h7/stm32h7.dtsi:364 */
		rtc: rtc@58004000 {
			compatible = "st,stm32-rtc";    /* in Engineer-sdk/zephyr/dts/arm/st/h7/stm32h7.dtsi:365 */
			reg = < 0x58004000 0x400 >;     /* in Engineer-sdk/zephyr/dts/arm/st/h7/stm32h7.dtsi:366 */
			interrupts = < 0x29 0x0 >;      /* in Engineer-sdk/zephyr/dts/arm/st/h7/stm32h7.dtsi:367 */
			clocks = < &rcc 0xf4 0x10000 >; /* in Engineer-sdk/zephyr/dts/arm/st/h7/stm32h7.dtsi:368 */
			prescaler = < 0x8000 >;         /* in Engineer-sdk/zephyr/dts/arm/st/h7/stm32h7.dtsi:369 */
			alarms-count = < 0x2 >;         /* in Engineer-sdk/zephyr/dts/arm/st/h7/stm32h7.dtsi:370 */
			alrm-exti-line = < 0x11 >;      /* in Engineer-sdk/zephyr/dts/arm/st/h7/stm32h7.dtsi:371 */
			status = "disabled";            /* in Engineer-sdk/zephyr/dts/arm/st/h7/stm32h7.dtsi:372 */

			/* node '/soc/rtc@58004000/backup_regs' defined in Engineer-sdk/zephyr/dts/arm/st/h7/stm32h723.dtsi:132 */
			bbram: backup_regs {
				compatible = "st,stm32-bbram"; /* in Engineer-sdk/zephyr/dts/arm/st/h7/stm32h723.dtsi:133 */
				st,backup-regs = < 0x20 >;     /* in Engineer-sdk/zephyr/dts/arm/st/h7/stm32h723.dtsi:134 */
				status = "disabled";           /* in Engineer-sdk/zephyr/dts/arm/st/h7/stm32h723.dtsi:135 */
			};
		};

		/* node '/soc/i2c@40005400' defined in Engineer-sdk/zephyr/dts/arm/st/h7/stm32h7.dtsi:375 */
		i2c1: i2c@40005400 {
			compatible = "st,stm32-i2c-v2";  /* in Engineer-sdk/zephyr/dts/arm/st/h7/stm32h7.dtsi:376 */
			clock-frequency = < 0x186a0 >;   /* in Engineer-sdk/zephyr/dts/arm/st/h7/stm32h7.dtsi:377 */
			#address-cells = < 0x1 >;        /* in Engineer-sdk/zephyr/dts/arm/st/h7/stm32h7.dtsi:378 */
			#size-cells = < 0x0 >;           /* in Engineer-sdk/zephyr/dts/arm/st/h7/stm32h7.dtsi:379 */
			reg = < 0x40005400 0x400 >;      /* in Engineer-sdk/zephyr/dts/arm/st/h7/stm32h7.dtsi:380 */
			clocks = < &rcc 0xe8 0x200000 >; /* in Engineer-sdk/zephyr/dts/arm/st/h7/stm32h7.dtsi:381 */
			interrupts = < 0x1f 0x0 >,
			             < 0x20 0x0 >;       /* in Engineer-sdk/zephyr/dts/arm/st/h7/stm32h7.dtsi:382 */
			interrupt-names = "event",
			                  "error";       /* in Engineer-sdk/zephyr/dts/arm/st/h7/stm32h7.dtsi:383 */
			status = "disabled";             /* in Engineer-sdk/zephyr/dts/arm/st/h7/stm32h7.dtsi:384 */
			phandle = < 0x26 >;              /* in Engineer-sdk/zephyr/dts/arm/st/h7/stm32h7.dtsi:1166 */
		};

		/* node '/soc/i2c@40005800' defined in Engineer-sdk/zephyr/dts/arm/st/h7/stm32h7.dtsi:387 */
		i2c2: i2c@40005800 {
			compatible = "st,stm32-i2c-v2";  /* in Engineer-sdk/zephyr/dts/arm/st/h7/stm32h7.dtsi:388 */
			clock-frequency = < 0x186a0 >;   /* in Engineer-sdk/zephyr/dts/arm/st/h7/stm32h7.dtsi:389 */
			#address-cells = < 0x1 >;        /* in Engineer-sdk/zephyr/dts/arm/st/h7/stm32h7.dtsi:390 */
			#size-cells = < 0x0 >;           /* in Engineer-sdk/zephyr/dts/arm/st/h7/stm32h7.dtsi:391 */
			reg = < 0x40005800 0x400 >;      /* in Engineer-sdk/zephyr/dts/arm/st/h7/stm32h7.dtsi:392 */
			clocks = < &rcc 0xe8 0x400000 >; /* in Engineer-sdk/zephyr/dts/arm/st/h7/stm32h7.dtsi:393 */
			interrupts = < 0x21 0x0 >,
			             < 0x22 0x0 >;       /* in Engineer-sdk/zephyr/dts/arm/st/h7/stm32h7.dtsi:394 */
			interrupt-names = "event",
			                  "error";       /* in Engineer-sdk/zephyr/dts/arm/st/h7/stm32h7.dtsi:395 */
			status = "disabled";             /* in Engineer-sdk/zephyr/dts/arm/st/h7/stm32h7.dtsi:396 */
			phandle = < 0x27 >;              /* in Engineer-sdk/zephyr/dts/arm/st/h7/stm32h7.dtsi:1174 */
		};

		/* node '/soc/i2c@40005c00' defined in Engineer-sdk/zephyr/dts/arm/st/h7/stm32h7.dtsi:399 */
		i2c3: i2c@40005c00 {
			compatible = "st,stm32-i2c-v2";  /* in Engineer-sdk/zephyr/dts/arm/st/h7/stm32h7.dtsi:400 */
			clock-frequency = < 0x186a0 >;   /* in Engineer-sdk/zephyr/dts/arm/st/h7/stm32h7.dtsi:401 */
			#address-cells = < 0x1 >;        /* in Engineer-sdk/zephyr/dts/arm/st/h7/stm32h7.dtsi:402 */
			#size-cells = < 0x0 >;           /* in Engineer-sdk/zephyr/dts/arm/st/h7/stm32h7.dtsi:403 */
			reg = < 0x40005c00 0x400 >;      /* in Engineer-sdk/zephyr/dts/arm/st/h7/stm32h7.dtsi:404 */
			clocks = < &rcc 0xe8 0x800000 >; /* in Engineer-sdk/zephyr/dts/arm/st/h7/stm32h7.dtsi:405 */
			interrupts = < 0x48 0x0 >,
			             < 0x49 0x0 >;       /* in Engineer-sdk/zephyr/dts/arm/st/h7/stm32h7.dtsi:406 */
			interrupt-names = "event",
			                  "error";       /* in Engineer-sdk/zephyr/dts/arm/st/h7/stm32h7.dtsi:407 */
			status = "disabled";             /* in Engineer-sdk/zephyr/dts/arm/st/h7/stm32h7.dtsi:408 */
			phandle = < 0x28 >;              /* in Engineer-sdk/zephyr/dts/arm/st/h7/stm32h7.dtsi:1182 */
		};

		/* node '/soc/i2c@58001c00' defined in Engineer-sdk/zephyr/dts/arm/st/h7/stm32h7.dtsi:411 */
		i2c4: i2c@58001c00 {
			compatible = "st,stm32-i2c-v2"; /* in Engineer-sdk/zephyr/dts/arm/st/h7/stm32h7.dtsi:412 */
			clock-frequency = < 0x186a0 >;  /* in Engineer-sdk/zephyr/dts/arm/st/h7/stm32h7.dtsi:413 */
			#address-cells = < 0x1 >;       /* in Engineer-sdk/zephyr/dts/arm/st/h7/stm32h7.dtsi:414 */
			#size-cells = < 0x0 >;          /* in Engineer-sdk/zephyr/dts/arm/st/h7/stm32h7.dtsi:415 */
			reg = < 0x58001c00 0x400 >;     /* in Engineer-sdk/zephyr/dts/arm/st/h7/stm32h7.dtsi:416 */
			clocks = < &rcc 0xf4 0x80 >;    /* in Engineer-sdk/zephyr/dts/arm/st/h7/stm32h7.dtsi:417 */
			interrupts = < 0x5f 0x0 >,
			             < 0x60 0x0 >;      /* in Engineer-sdk/zephyr/dts/arm/st/h7/stm32h7.dtsi:418 */
			interrupt-names = "event",
			                  "error";      /* in Engineer-sdk/zephyr/dts/arm/st/h7/stm32h7.dtsi:419 */
			status = "disabled";            /* in Engineer-sdk/zephyr/dts/arm/st/h7/stm32h7.dtsi:420 */
			phandle = < 0x29 >;             /* in Engineer-sdk/zephyr/dts/arm/st/h7/stm32h7.dtsi:1190 */
		};

		/* node '/soc/spi@40013000' defined in Engineer-sdk/zephyr/dts/arm/st/h7/stm32h7.dtsi:423 */
		spi1: spi@40013000 {
			compatible = "st,stm32h7-spi",
			             "st,stm32-spi-fifo",
			             "st,stm32-spi";      /* in Engineer-sdk/zephyr/dts/arm/st/h7/stm32h7.dtsi:424 */
			#address-cells = < 0x1 >;         /* in Engineer-sdk/zephyr/dts/arm/st/h7/stm32h7.dtsi:425 */
			#size-cells = < 0x0 >;            /* in Engineer-sdk/zephyr/dts/arm/st/h7/stm32h7.dtsi:426 */
			reg = < 0x40013000 0x400 >;       /* in Engineer-sdk/zephyr/dts/arm/st/h7/stm32h7.dtsi:427 */
			clocks = < &rcc 0xf0 0x1000 >,
			         < &rcc 0x9 0x1cc0050 >;  /* in Engineer-sdk/zephyr/dts/arm/st/h7/stm32h7.dtsi:428 */
			interrupts = < 0x23 0x0 >;        /* in Engineer-sdk/zephyr/dts/arm/st/h7/stm32h7.dtsi:430 */
			status = "disabled";              /* in Engineer-sdk/zephyr/dts/arm/st/h7/stm32h7.dtsi:431 */
		};

		/* node '/soc/spi@40003800' defined in Engineer-sdk/zephyr/dts/arm/st/h7/stm32h7.dtsi:434 */
		spi2: spi@40003800 {
			compatible = "st,stm32h7-spi",
			             "st,stm32-spi-fifo",
			             "st,stm32-spi";                                    /* in Engineer-sdk/zephyr/dts/arm/st/h7/stm32h7.dtsi:435 */
			#address-cells = < 0x1 >;                                       /* in Engineer-sdk/zephyr/dts/arm/st/h7/stm32h7.dtsi:436 */
			#size-cells = < 0x0 >;                                          /* in Engineer-sdk/zephyr/dts/arm/st/h7/stm32h7.dtsi:437 */
			reg = < 0x40003800 0x400 >;                                     /* in Engineer-sdk/zephyr/dts/arm/st/h7/stm32h7.dtsi:438 */
			interrupts = < 0x24 0x0 >;                                      /* in Engineer-sdk/zephyr/dts/arm/st/h7/stm32h7.dtsi:441 */
			status = "okay";                                                /* in Engineer-manifest/boards/damiao/mc02/damiao_mc02.dts:143 */
			clocks = < &rcc 0xe8 0x4000 >,
			         < &rcc 0xb 0x1cc0050 >;                                /* in Engineer-manifest/boards/damiao/mc02/damiao_mc02.dts:144 */
			pinctrl-0 = < &spi2_sck_pb13 &spi2_miso_pc2_c &spi2_mosi_pc1 >; /* in Engineer-manifest/boards/damiao/mc02/damiao_mc02.dts:146 */
			pinctrl-names = "default";                                      /* in Engineer-manifest/boards/damiao/mc02/damiao_mc02.dts:147 */
			cs-gpios = < &gpioc 0x0 0x0 >,
			           < &gpioc 0x3 0x0 >;                                  /* in Engineer-manifest/boards/damiao/mc02/damiao_mc02.dts:148 */
			dmas = < &dmamux1 0x1 0x28 0x440 >,
			       < &dmamux1 0x4 0x27 0x480 >;                             /* in Engineer-manifest/boards/damiao/mc02/damiao_mc02.dts:150 */
			dma-names = "spi1-tx",
			            "spi1-rx";                                          /* in Engineer-manifest/boards/damiao/mc02/damiao_mc02.dts:152 */

			/* node '/soc/spi@40003800/bmi08x@0' defined in Engineer-manifest/boards/damiao/mc02/damiao_mc02.dts:154 */
			bmi08x_accel: bmi08x@0 {
				compatible = "bosch,bmi08x-accel"; /* in Engineer-manifest/boards/damiao/mc02/damiao_mc02.dts:155 */
				reg = < 0x0 >;                     /* in Engineer-manifest/boards/damiao/mc02/damiao_mc02.dts:157 */
				spi-max-frequency = < 0x7a1200 >;  /* in Engineer-manifest/boards/damiao/mc02/damiao_mc02.dts:158 */
				int-gpios = < &gpioe 0xa 0x0 >;    /* in Engineer-manifest/boards/damiao/mc02/damiao_mc02.dts:160 */
				int1-map-io = < 0x1 >;             /* in Engineer-manifest/boards/damiao/mc02/damiao_mc02.dts:161 */
				int2-map-io = < 0x0 >;             /* in Engineer-manifest/boards/damiao/mc02/damiao_mc02.dts:162 */
				int1-conf-io = < 0x4 >;            /* in Engineer-manifest/boards/damiao/mc02/damiao_mc02.dts:163 */
				int2-conf-io = < 0x0 >;            /* in Engineer-manifest/boards/damiao/mc02/damiao_mc02.dts:164 */
				accel-hz = "800";                  /* in Engineer-manifest/boards/damiao/mc02/damiao_mc02.dts:165 */
				accel-fs = < 0x18 >;               /* in Engineer-manifest/boards/damiao/mc02/damiao_mc02.dts:166 */
				data-sync = < &bmi08x_gyro >;      /* in Engineer-manifest/boards/damiao/mc02/damiao_mc02.dts:167 */
			};

			/* node '/soc/spi@40003800/bmi08x@1' defined in Engineer-manifest/boards/damiao/mc02/damiao_mc02.dts:170 */
			bmi08x_gyro: bmi08x@1 {
				compatible = "bosch,bmi08x-gyro"; /* in Engineer-manifest/boards/damiao/mc02/damiao_mc02.dts:171 */
				reg = < 0x1 >;                    /* in Engineer-manifest/boards/damiao/mc02/damiao_mc02.dts:173 */
				spi-max-frequency = < 0x7a1200 >; /* in Engineer-manifest/boards/damiao/mc02/damiao_mc02.dts:174 */
				int-gpios = < &gpioe 0xc 0x0 >;   /* in Engineer-manifest/boards/damiao/mc02/damiao_mc02.dts:176 */
				int3-4-map-io = < 0x1 >;          /* in Engineer-manifest/boards/damiao/mc02/damiao_mc02.dts:177 */
				int3-4-conf-io = < 0x2 >;         /* in Engineer-manifest/boards/damiao/mc02/damiao_mc02.dts:178 */
				gyro-hz = "1000_116";             /* in Engineer-manifest/boards/damiao/mc02/damiao_mc02.dts:179 */
				gyro-fs = < 0x3e8 >;              /* in Engineer-manifest/boards/damiao/mc02/damiao_mc02.dts:180 */
				data-sync;                        /* in Engineer-manifest/boards/damiao/mc02/damiao_mc02.dts:181 */
				phandle = < 0x17 >;               /* in Engineer-manifest/boards/damiao/mc02/damiao_mc02.dts:167 */
			};
		};

		/* node '/soc/spi@40003c00' defined in Engineer-sdk/zephyr/dts/arm/st/h7/stm32h7.dtsi:445 */
		spi3: spi@40003c00 {
			compatible = "st,stm32h7-spi",
			             "st,stm32-spi-fifo",
			             "st,stm32-spi";      /* in Engineer-sdk/zephyr/dts/arm/st/h7/stm32h7.dtsi:446 */
			#address-cells = < 0x1 >;         /* in Engineer-sdk/zephyr/dts/arm/st/h7/stm32h7.dtsi:447 */
			#size-cells = < 0x0 >;            /* in Engineer-sdk/zephyr/dts/arm/st/h7/stm32h7.dtsi:448 */
			reg = < 0x40003c00 0x400 >;       /* in Engineer-sdk/zephyr/dts/arm/st/h7/stm32h7.dtsi:449 */
			clocks = < &rcc 0xe8 0x8000 >,
			         < &rcc 0x9 0x1cc0050 >;  /* in Engineer-sdk/zephyr/dts/arm/st/h7/stm32h7.dtsi:450 */
			interrupts = < 0x33 0x0 >;        /* in Engineer-sdk/zephyr/dts/arm/st/h7/stm32h7.dtsi:452 */
			status = "disabled";              /* in Engineer-sdk/zephyr/dts/arm/st/h7/stm32h7.dtsi:453 */
		};

		/* node '/soc/spi@40013400' defined in Engineer-sdk/zephyr/dts/arm/st/h7/stm32h7.dtsi:456 */
		spi4: spi@40013400 {
			compatible = "st,stm32h7-spi",
			             "st,stm32-spi-fifo",
			             "st,stm32-spi";      /* in Engineer-sdk/zephyr/dts/arm/st/h7/stm32h7.dtsi:457 */
			#address-cells = < 0x1 >;         /* in Engineer-sdk/zephyr/dts/arm/st/h7/stm32h7.dtsi:458 */
			#size-cells = < 0x0 >;            /* in Engineer-sdk/zephyr/dts/arm/st/h7/stm32h7.dtsi:459 */
			reg = < 0x40013400 0x400 >;       /* in Engineer-sdk/zephyr/dts/arm/st/h7/stm32h7.dtsi:460 */
			clocks = < &rcc 0xf0 0x2000 >;    /* in Engineer-sdk/zephyr/dts/arm/st/h7/stm32h7.dtsi:461 */
			interrupts = < 0x54 0x0 >;        /* in Engineer-sdk/zephyr/dts/arm/st/h7/stm32h7.dtsi:462 */
			status = "disabled";              /* in Engineer-sdk/zephyr/dts/arm/st/h7/stm32h7.dtsi:463 */
		};

		/* node '/soc/spi@40015000' defined in Engineer-sdk/zephyr/dts/arm/st/h7/stm32h7.dtsi:466 */
		spi5: spi@40015000 {
			compatible = "st,stm32h7-spi",
			             "st,stm32-spi-fifo",
			             "st,stm32-spi";      /* in Engineer-sdk/zephyr/dts/arm/st/h7/stm32h7.dtsi:467 */
			#address-cells = < 0x1 >;         /* in Engineer-sdk/zephyr/dts/arm/st/h7/stm32h7.dtsi:468 */
			#size-cells = < 0x0 >;            /* in Engineer-sdk/zephyr/dts/arm/st/h7/stm32h7.dtsi:469 */
			reg = < 0x40015000 0x400 >;       /* in Engineer-sdk/zephyr/dts/arm/st/h7/stm32h7.dtsi:470 */
			clocks = < &rcc 0xf0 0x100000 >;  /* in Engineer-sdk/zephyr/dts/arm/st/h7/stm32h7.dtsi:471 */
			interrupts = < 0x55 0x0 >;        /* in Engineer-sdk/zephyr/dts/arm/st/h7/stm32h7.dtsi:472 */
			status = "disabled";              /* in Engineer-sdk/zephyr/dts/arm/st/h7/stm32h7.dtsi:473 */
		};

		/* node '/soc/spi@58001400' defined in Engineer-sdk/zephyr/dts/arm/st/h7/stm32h7.dtsi:476 */
		spi6: spi@58001400 {
			compatible = "st,stm32h7-spi",
			             "st,stm32-spi-fifo",
			             "st,stm32-spi";                  /* in Engineer-sdk/zephyr/dts/arm/st/h7/stm32h7.dtsi:477 */
			#address-cells = < 0x1 >;                     /* in Engineer-sdk/zephyr/dts/arm/st/h7/stm32h7.dtsi:478 */
			#size-cells = < 0x0 >;                        /* in Engineer-sdk/zephyr/dts/arm/st/h7/stm32h7.dtsi:479 */
			reg = < 0x58001400 0x400 >;                   /* in Engineer-sdk/zephyr/dts/arm/st/h7/stm32h7.dtsi:480 */
			interrupts = < 0x56 0x0 >;                    /* in Engineer-sdk/zephyr/dts/arm/st/h7/stm32h7.dtsi:482 */
			status = "okay";                              /* in Engineer-manifest/boards/damiao/mc02/damiao_mc02.dts:187 */
			clocks = < &rcc 0xf4 0x20 >,
			         < &rcc 0xc 0x9dc0058 >;              /* in Engineer-manifest/boards/damiao/mc02/damiao_mc02.dts:188 */
			pinctrl-0 = < &spi6_sck_pa5 &spi6_mosi_pa7 >; /* in Engineer-manifest/boards/damiao/mc02/damiao_mc02.dts:190 */
			pinctrl-names = "default";                    /* in Engineer-manifest/boards/damiao/mc02/damiao_mc02.dts:191 */

			/* node '/soc/spi@58001400/ws2812@0' defined in Engineer-manifest/boards/damiao/mc02/damiao_mc02.dts:193 */
			rgb_led: ws2812@0 {
				compatible = "worldsemi,ws2812-spi"; /* in Engineer-manifest/boards/damiao/mc02/damiao_mc02.dts:194 */
				reg = < 0x0 >;                       /* in Engineer-manifest/boards/damiao/mc02/damiao_mc02.dts:196 */
				spi-max-frequency = < 0x3d0900 >;    /* in Engineer-manifest/boards/damiao/mc02/damiao_mc02.dts:197 */
				frame-format = < 0x8000 >;           /* in Engineer-manifest/boards/damiao/mc02/damiao_mc02.dts:198 */
				chain-length = < 0x1 >;              /* in Engineer-manifest/boards/damiao/mc02/damiao_mc02.dts:200 */
				spi-one-frame = < 0x70 >;            /* in Engineer-manifest/boards/damiao/mc02/damiao_mc02.dts:201 */
				spi-zero-frame = < 0x40 >;           /* in Engineer-manifest/boards/damiao/mc02/damiao_mc02.dts:202 */
				color-mapping = < 0x2 >,
				                < 0x1 >,
				                < 0x3 >;             /* in Engineer-manifest/boards/damiao/mc02/damiao_mc02.dts:203 */
				reset-delay = < 0xfa >;              /* in Engineer-manifest/boards/damiao/mc02/damiao_mc02.dts:206 */
			};
		};

		/* node '/soc/i2s@40013000' defined in Engineer-sdk/zephyr/dts/arm/st/h7/stm32h7.dtsi:486 */
		i2s1: i2s@40013000 {
			compatible = "st,stm32h7-i2s",
			             "st,stm32-i2s";                                    /* in Engineer-sdk/zephyr/dts/arm/st/h7/stm32h7.dtsi:487 */
			#address-cells = < 0x1 >;                                       /* in Engineer-sdk/zephyr/dts/arm/st/h7/stm32h7.dtsi:488 */
			#size-cells = < 0x0 >;                                          /* in Engineer-sdk/zephyr/dts/arm/st/h7/stm32h7.dtsi:489 */
			reg = < 0x40013000 0x400 >;                                     /* in Engineer-sdk/zephyr/dts/arm/st/h7/stm32h7.dtsi:490 */
			clocks = < &rcc 0xf0 0x1000 >,
			         < &rcc 0x9 0x1cc0050 >;                                /* in Engineer-sdk/zephyr/dts/arm/st/h7/stm32h7.dtsi:491 */
			dmas = < &dmamux1 0x0 0x26 0x20440 &dmamux1 0x1 0x25 0x20480 >; /* in Engineer-sdk/zephyr/dts/arm/st/h7/stm32h7.dtsi:493 */
			dma-names = "tx",
			            "rx";                                               /* in Engineer-sdk/zephyr/dts/arm/st/h7/stm32h7.dtsi:495 */
			interrupts = < 0x23 0x3 >;                                      /* in Engineer-sdk/zephyr/dts/arm/st/h7/stm32h7.dtsi:496 */
			status = "disabled";                                            /* in Engineer-sdk/zephyr/dts/arm/st/h7/stm32h7.dtsi:497 */
		};

		/* node '/soc/i2s@40003800' defined in Engineer-sdk/zephyr/dts/arm/st/h7/stm32h7.dtsi:500 */
		i2s2: i2s@40003800 {
			compatible = "st,stm32h7-i2s",
			             "st,stm32-i2s";                                    /* in Engineer-sdk/zephyr/dts/arm/st/h7/stm32h7.dtsi:501 */
			#address-cells = < 0x1 >;                                       /* in Engineer-sdk/zephyr/dts/arm/st/h7/stm32h7.dtsi:502 */
			#size-cells = < 0x0 >;                                          /* in Engineer-sdk/zephyr/dts/arm/st/h7/stm32h7.dtsi:503 */
			reg = < 0x40003800 0x400 >;                                     /* in Engineer-sdk/zephyr/dts/arm/st/h7/stm32h7.dtsi:504 */
			clocks = < &rcc 0xe8 0x4000 >,
			         < &rcc 0x9 0x1cc0050 >;                                /* in Engineer-sdk/zephyr/dts/arm/st/h7/stm32h7.dtsi:505 */
			dmas = < &dmamux1 0x0 0x28 0x20440 &dmamux1 0x1 0x27 0x20480 >; /* in Engineer-sdk/zephyr/dts/arm/st/h7/stm32h7.dtsi:507 */
			dma-names = "tx",
			            "rx";                                               /* in Engineer-sdk/zephyr/dts/arm/st/h7/stm32h7.dtsi:509 */
			interrupts = < 0x24 0x0 >;                                      /* in Engineer-sdk/zephyr/dts/arm/st/h7/stm32h7.dtsi:510 */
			status = "disabled";                                            /* in Engineer-sdk/zephyr/dts/arm/st/h7/stm32h7.dtsi:511 */
		};

		/* node '/soc/i2s@40003c00' defined in Engineer-sdk/zephyr/dts/arm/st/h7/stm32h7.dtsi:514 */
		i2s3: i2s@40003c00 {
			compatible = "st,stm32h7-i2s",
			             "st,stm32-i2s";                                    /* in Engineer-sdk/zephyr/dts/arm/st/h7/stm32h7.dtsi:515 */
			#address-cells = < 0x1 >;                                       /* in Engineer-sdk/zephyr/dts/arm/st/h7/stm32h7.dtsi:516 */
			#size-cells = < 0x0 >;                                          /* in Engineer-sdk/zephyr/dts/arm/st/h7/stm32h7.dtsi:517 */
			reg = < 0x40003c00 0x400 >;                                     /* in Engineer-sdk/zephyr/dts/arm/st/h7/stm32h7.dtsi:518 */
			clocks = < &rcc 0xe8 0x8000 >,
			         < &rcc 0x9 0x1cc0050 >;                                /* in Engineer-sdk/zephyr/dts/arm/st/h7/stm32h7.dtsi:519 */
			dmas = < &dmamux1 0x0 0x3e 0x20440 &dmamux1 0x1 0x3d 0x20480 >; /* in Engineer-sdk/zephyr/dts/arm/st/h7/stm32h7.dtsi:521 */
			dma-names = "tx",
			            "rx";                                               /* in Engineer-sdk/zephyr/dts/arm/st/h7/stm32h7.dtsi:523 */
			interrupts = < 0x33 0x0 >;                                      /* in Engineer-sdk/zephyr/dts/arm/st/h7/stm32h7.dtsi:524 */
			status = "disabled";                                            /* in Engineer-sdk/zephyr/dts/arm/st/h7/stm32h7.dtsi:525 */
		};

		/* node '/soc/can@4000a000' defined in Engineer-sdk/zephyr/dts/arm/st/h7/stm32h7.dtsi:528 */
		fdcan1: can@4000a000 {
			compatible = "st,stm32h7-fdcan";                       /* in Engineer-sdk/zephyr/dts/arm/st/h7/stm32h7.dtsi:529 */
			reg = < 0x4000a000 0x400 >,
			      < 0x4000ac00 0x350 >;                            /* in Engineer-sdk/zephyr/dts/arm/st/h7/stm32h7.dtsi:530 */
			reg-names = "m_can",
			            "message_ram";                             /* in Engineer-sdk/zephyr/dts/arm/st/h7/stm32h7.dtsi:531 */
			interrupts = < 0x13 0x0 >,
			             < 0x15 0x0 >,
			             < 0x3f 0x0 >;                             /* in Engineer-sdk/zephyr/dts/arm/st/h7/stm32h7.dtsi:533 */
			interrupt-names = "int0",
			                  "int1",
			                  "calib";                             /* in Engineer-sdk/zephyr/dts/arm/st/h7/stm32h7.dtsi:534 */
			status = "okay";                                       /* in Engineer-manifest/boards/damiao/mc02/damiao_mc02.dts:316 */
			bosch,mram-cfg = < 0x0 0x1c 0x8 0x3 0x3 0x0 0x3 0x3 >; /* in Engineer-manifest/boards/damiao/mc02/damiao_mc02.dts:317 */
			clocks = < &rcc 0xec 0x100 >,
			         < &rcc 0xc 0x10dc0050 >;                      /* in Engineer-manifest/boards/damiao/mc02/damiao_mc02.dts:318 */
			pinctrl-0 = < &fdcan1_rx_pd0 &fdcan1_tx_pd1 >;         /* in Engineer-manifest/boards/damiao/mc02/damiao_mc02.dts:320 */
			pinctrl-names = "default";                             /* in Engineer-manifest/boards/damiao/mc02/damiao_mc02.dts:321 */
		};

		/* node '/soc/can@4000a400' defined in Engineer-sdk/zephyr/dts/arm/st/h7/stm32h7.dtsi:539 */
		fdcan2: can@4000a400 {
			compatible = "st,stm32h7-fdcan";                       /* in Engineer-sdk/zephyr/dts/arm/st/h7/stm32h7.dtsi:540 */
			reg = < 0x4000a400 0x400 >,
			      < 0x4000ac00 0x6a0 >;                            /* in Engineer-sdk/zephyr/dts/arm/st/h7/stm32h7.dtsi:541 */
			reg-names = "m_can",
			            "message_ram";                             /* in Engineer-sdk/zephyr/dts/arm/st/h7/stm32h7.dtsi:542 */
			interrupts = < 0x14 0x0 >,
			             < 0x16 0x0 >,
			             < 0x3f 0x0 >;                             /* in Engineer-sdk/zephyr/dts/arm/st/h7/stm32h7.dtsi:544 */
			interrupt-names = "int0",
			                  "int1",
			                  "calib";                             /* in Engineer-sdk/zephyr/dts/arm/st/h7/stm32h7.dtsi:545 */
			status = "okay";                                       /* in Engineer-manifest/boards/damiao/mc02/damiao_mc02.dts:325 */
			bosch,mram-cfg = < 0x0 0x1c 0x8 0x3 0x3 0x0 0x3 0x3 >; /* in Engineer-manifest/boards/damiao/mc02/damiao_mc02.dts:326 */
			clocks = < &rcc 0xec 0x100 >,
			         < &rcc 0xc 0x10dc0050 >;                      /* in Engineer-manifest/boards/damiao/mc02/damiao_mc02.dts:327 */
			pinctrl-0 = < &fdcan2_rx_pb5 &fdcan2_tx_pb6 >;         /* in Engineer-manifest/boards/damiao/mc02/damiao_mc02.dts:329 */
			pinctrl-names = "default";                             /* in Engineer-manifest/boards/damiao/mc02/damiao_mc02.dts:330 */
		};

		/* node '/soc/timers@40010000' defined in Engineer-sdk/zephyr/dts/arm/st/h7/stm32h7.dtsi:550 */
		timers1: timers@40010000 {
			compatible = "st,stm32-timers"; /* in Engineer-sdk/zephyr/dts/arm/st/h7/stm32h7.dtsi:551 */
			reg = < 0x40010000 0x400 >;     /* in Engineer-sdk/zephyr/dts/arm/st/h7/stm32h7.dtsi:552 */
			clocks = < &rcc 0xf0 0x1 >,
			         < &rcc 0x13 0xff >;    /* in Engineer-sdk/zephyr/dts/arm/st/h7/stm32h7.dtsi:553 */
			resets = < &rctl 0x1300 >;      /* in Engineer-sdk/zephyr/dts/arm/st/h7/stm32h7.dtsi:555 */
			interrupts = < 0x18 0x0 >,
			             < 0x19 0x0 >,
			             < 0x1a 0x0 >,
			             < 0x1b 0x0 >;      /* in Engineer-sdk/zephyr/dts/arm/st/h7/stm32h7.dtsi:556 */
			interrupt-names = "brk",
			                  "up",
			                  "trgcom",
			                  "cc";         /* in Engineer-sdk/zephyr/dts/arm/st/h7/stm32h7.dtsi:557 */
			st,prescaler = < 0x0 >;         /* in Engineer-sdk/zephyr/dts/arm/st/h7/stm32h7.dtsi:558 */
			status = "disabled";            /* in Engineer-sdk/zephyr/dts/arm/st/h7/stm32h7.dtsi:559 */

			/* node '/soc/timers@40010000/pwm' defined in Engineer-sdk/zephyr/dts/arm/st/h7/stm32h7.dtsi:561 */
			pwm {
				compatible = "st,stm32-pwm"; /* in Engineer-sdk/zephyr/dts/arm/st/h7/stm32h7.dtsi:562 */
				status = "disabled";         /* in Engineer-sdk/zephyr/dts/arm/st/h7/stm32h7.dtsi:563 */
				#pwm-cells = < 0x3 >;        /* in Engineer-sdk/zephyr/dts/arm/st/h7/stm32h7.dtsi:564 */
			};
		};

		/* node '/soc/timers@40000000' defined in Engineer-sdk/zephyr/dts/arm/st/h7/stm32h7.dtsi:568 */
		timers2: timers@40000000 {
			compatible = "st,stm32-timers"; /* in Engineer-sdk/zephyr/dts/arm/st/h7/stm32h7.dtsi:569 */
			reg = < 0x40000000 0x400 >;     /* in Engineer-sdk/zephyr/dts/arm/st/h7/stm32h7.dtsi:570 */
			clocks = < &rcc 0xe8 0x1 >,
			         < &rcc 0x12 0xff >;    /* in Engineer-sdk/zephyr/dts/arm/st/h7/stm32h7.dtsi:571 */
			resets = < &rctl 0x1200 >;      /* in Engineer-sdk/zephyr/dts/arm/st/h7/stm32h7.dtsi:573 */
			interrupts = < 0x1c 0x0 >;      /* in Engineer-sdk/zephyr/dts/arm/st/h7/stm32h7.dtsi:574 */
			interrupt-names = "global";     /* in Engineer-sdk/zephyr/dts/arm/st/h7/stm32h7.dtsi:575 */
			st,prescaler = < 0x0 >;         /* in Engineer-sdk/zephyr/dts/arm/st/h7/stm32h7.dtsi:576 */
			status = "disabled";            /* in Engineer-sdk/zephyr/dts/arm/st/h7/stm32h7.dtsi:577 */

			/* node '/soc/timers@40000000/pwm' defined in Engineer-sdk/zephyr/dts/arm/st/h7/stm32h7.dtsi:579 */
			pwm {
				compatible = "st,stm32-pwm"; /* in Engineer-sdk/zephyr/dts/arm/st/h7/stm32h7.dtsi:580 */
				status = "disabled";         /* in Engineer-sdk/zephyr/dts/arm/st/h7/stm32h7.dtsi:581 */
				#pwm-cells = < 0x3 >;        /* in Engineer-sdk/zephyr/dts/arm/st/h7/stm32h7.dtsi:582 */
			};

			/* node '/soc/timers@40000000/counter' defined in Engineer-sdk/zephyr/dts/arm/st/h7/stm32h7.dtsi:585 */
			counter {
				compatible = "st,stm32-counter"; /* in Engineer-sdk/zephyr/dts/arm/st/h7/stm32h7.dtsi:586 */
				status = "disabled";             /* in Engineer-sdk/zephyr/dts/arm/st/h7/stm32h7.dtsi:587 */
			};
		};

		/* node '/soc/timers@40000400' defined in Engineer-sdk/zephyr/dts/arm/st/h7/stm32h7.dtsi:591 */
		timers3: timers@40000400 {
			compatible = "st,stm32-timers"; /* in Engineer-sdk/zephyr/dts/arm/st/h7/stm32h7.dtsi:592 */
			reg = < 0x40000400 0x400 >;     /* in Engineer-sdk/zephyr/dts/arm/st/h7/stm32h7.dtsi:593 */
			clocks = < &rcc 0xe8 0x2 >,
			         < &rcc 0x12 0xff >;    /* in Engineer-sdk/zephyr/dts/arm/st/h7/stm32h7.dtsi:594 */
			resets = < &rctl 0x1201 >;      /* in Engineer-sdk/zephyr/dts/arm/st/h7/stm32h7.dtsi:596 */
			interrupts = < 0x1d 0x0 >;      /* in Engineer-sdk/zephyr/dts/arm/st/h7/stm32h7.dtsi:597 */
			interrupt-names = "global";     /* in Engineer-sdk/zephyr/dts/arm/st/h7/stm32h7.dtsi:598 */
			st,prescaler = < 0x0 >;         /* in Engineer-sdk/zephyr/dts/arm/st/h7/stm32h7.dtsi:599 */
			status = "disabled";            /* in Engineer-sdk/zephyr/dts/arm/st/h7/stm32h7.dtsi:600 */

			/* node '/soc/timers@40000400/pwm' defined in Engineer-sdk/zephyr/dts/arm/st/h7/stm32h7.dtsi:602 */
			pwm {
				compatible = "st,stm32-pwm"; /* in Engineer-sdk/zephyr/dts/arm/st/h7/stm32h7.dtsi:603 */
				status = "disabled";         /* in Engineer-sdk/zephyr/dts/arm/st/h7/stm32h7.dtsi:604 */
				#pwm-cells = < 0x3 >;        /* in Engineer-sdk/zephyr/dts/arm/st/h7/stm32h7.dtsi:605 */
			};

			/* node '/soc/timers@40000400/counter' defined in Engineer-sdk/zephyr/dts/arm/st/h7/stm32h7.dtsi:608 */
			counter {
				compatible = "st,stm32-counter"; /* in Engineer-sdk/zephyr/dts/arm/st/h7/stm32h7.dtsi:609 */
				status = "disabled";             /* in Engineer-sdk/zephyr/dts/arm/st/h7/stm32h7.dtsi:610 */
			};
		};

		/* node '/soc/timers@40000800' defined in Engineer-sdk/zephyr/dts/arm/st/h7/stm32h7.dtsi:614 */
		timers4: timers@40000800 {
			compatible = "st,stm32-timers"; /* in Engineer-sdk/zephyr/dts/arm/st/h7/stm32h7.dtsi:615 */
			reg = < 0x40000800 0x400 >;     /* in Engineer-sdk/zephyr/dts/arm/st/h7/stm32h7.dtsi:616 */
			clocks = < &rcc 0xe8 0x4 >,
			         < &rcc 0x12 0xff >;    /* in Engineer-sdk/zephyr/dts/arm/st/h7/stm32h7.dtsi:617 */
			resets = < &rctl 0x1202 >;      /* in Engineer-sdk/zephyr/dts/arm/st/h7/stm32h7.dtsi:619 */
			interrupts = < 0x1e 0x0 >;      /* in Engineer-sdk/zephyr/dts/arm/st/h7/stm32h7.dtsi:620 */
			interrupt-names = "global";     /* in Engineer-sdk/zephyr/dts/arm/st/h7/stm32h7.dtsi:621 */
			st,prescaler = < 0x0 >;         /* in Engineer-sdk/zephyr/dts/arm/st/h7/stm32h7.dtsi:622 */
			status = "disabled";            /* in Engineer-sdk/zephyr/dts/arm/st/h7/stm32h7.dtsi:623 */

			/* node '/soc/timers@40000800/pwm' defined in Engineer-sdk/zephyr/dts/arm/st/h7/stm32h7.dtsi:625 */
			pwm {
				compatible = "st,stm32-pwm"; /* in Engineer-sdk/zephyr/dts/arm/st/h7/stm32h7.dtsi:626 */
				status = "disabled";         /* in Engineer-sdk/zephyr/dts/arm/st/h7/stm32h7.dtsi:627 */
				#pwm-cells = < 0x3 >;        /* in Engineer-sdk/zephyr/dts/arm/st/h7/stm32h7.dtsi:628 */
			};

			/* node '/soc/timers@40000800/counter' defined in Engineer-sdk/zephyr/dts/arm/st/h7/stm32h7.dtsi:631 */
			counter {
				compatible = "st,stm32-counter"; /* in Engineer-sdk/zephyr/dts/arm/st/h7/stm32h7.dtsi:632 */
				status = "disabled";             /* in Engineer-sdk/zephyr/dts/arm/st/h7/stm32h7.dtsi:633 */
			};
		};

		/* node '/soc/timers@40000c00' defined in Engineer-sdk/zephyr/dts/arm/st/h7/stm32h7.dtsi:637 */
		timers5: timers@40000c00 {
			compatible = "st,stm32-timers"; /* in Engineer-sdk/zephyr/dts/arm/st/h7/stm32h7.dtsi:638 */
			reg = < 0x40000c00 0x400 >;     /* in Engineer-sdk/zephyr/dts/arm/st/h7/stm32h7.dtsi:639 */
			clocks = < &rcc 0xe8 0x8 >,
			         < &rcc 0x12 0xff >;    /* in Engineer-sdk/zephyr/dts/arm/st/h7/stm32h7.dtsi:640 */
			resets = < &rctl 0x1203 >;      /* in Engineer-sdk/zephyr/dts/arm/st/h7/stm32h7.dtsi:642 */
			interrupts = < 0x32 0x0 >;      /* in Engineer-sdk/zephyr/dts/arm/st/h7/stm32h7.dtsi:643 */
			interrupt-names = "global";     /* in Engineer-sdk/zephyr/dts/arm/st/h7/stm32h7.dtsi:644 */
			st,prescaler = < 0x0 >;         /* in Engineer-sdk/zephyr/dts/arm/st/h7/stm32h7.dtsi:645 */
			status = "disabled";            /* in Engineer-sdk/zephyr/dts/arm/st/h7/stm32h7.dtsi:646 */

			/* node '/soc/timers@40000c00/pwm' defined in Engineer-sdk/zephyr/dts/arm/st/h7/stm32h7.dtsi:648 */
			pwm {
				compatible = "st,stm32-pwm"; /* in Engineer-sdk/zephyr/dts/arm/st/h7/stm32h7.dtsi:649 */
				status = "disabled";         /* in Engineer-sdk/zephyr/dts/arm/st/h7/stm32h7.dtsi:650 */
				#pwm-cells = < 0x3 >;        /* in Engineer-sdk/zephyr/dts/arm/st/h7/stm32h7.dtsi:651 */
			};

			/* node '/soc/timers@40000c00/counter' defined in Engineer-sdk/zephyr/dts/arm/st/h7/stm32h7.dtsi:654 */
			counter {
				compatible = "st,stm32-counter"; /* in Engineer-sdk/zephyr/dts/arm/st/h7/stm32h7.dtsi:655 */
				status = "disabled";             /* in Engineer-sdk/zephyr/dts/arm/st/h7/stm32h7.dtsi:656 */
			};
		};

		/* node '/soc/timers@40001000' defined in Engineer-sdk/zephyr/dts/arm/st/h7/stm32h7.dtsi:660 */
		timers6: timers@40001000 {
			compatible = "st,stm32-timers"; /* in Engineer-sdk/zephyr/dts/arm/st/h7/stm32h7.dtsi:661 */
			reg = < 0x40001000 0x400 >;     /* in Engineer-sdk/zephyr/dts/arm/st/h7/stm32h7.dtsi:662 */
			clocks = < &rcc 0xe8 0x10 >,
			         < &rcc 0x12 0xff >;    /* in Engineer-sdk/zephyr/dts/arm/st/h7/stm32h7.dtsi:663 */
			resets = < &rctl 0x1204 >;      /* in Engineer-sdk/zephyr/dts/arm/st/h7/stm32h7.dtsi:665 */
			interrupts = < 0x36 0x0 >;      /* in Engineer-sdk/zephyr/dts/arm/st/h7/stm32h7.dtsi:666 */
			interrupt-names = "global";     /* in Engineer-sdk/zephyr/dts/arm/st/h7/stm32h7.dtsi:667 */
			st,prescaler = < 0x0 >;         /* in Engineer-sdk/zephyr/dts/arm/st/h7/stm32h7.dtsi:668 */
			status = "disabled";            /* in Engineer-sdk/zephyr/dts/arm/st/h7/stm32h7.dtsi:669 */

			/* node '/soc/timers@40001000/counter' defined in Engineer-sdk/zephyr/dts/arm/st/h7/stm32h7.dtsi:671 */
			counter {
				compatible = "st,stm32-counter"; /* in Engineer-sdk/zephyr/dts/arm/st/h7/stm32h7.dtsi:672 */
				status = "disabled";             /* in Engineer-sdk/zephyr/dts/arm/st/h7/stm32h7.dtsi:673 */
			};
		};

		/* node '/soc/timers@40001400' defined in Engineer-sdk/zephyr/dts/arm/st/h7/stm32h7.dtsi:677 */
		timers7: timers@40001400 {
			compatible = "st,stm32-timers"; /* in Engineer-sdk/zephyr/dts/arm/st/h7/stm32h7.dtsi:678 */
			reg = < 0x40001400 0x400 >;     /* in Engineer-sdk/zephyr/dts/arm/st/h7/stm32h7.dtsi:679 */
			clocks = < &rcc 0xe8 0x20 >,
			         < &rcc 0x12 0xff >;    /* in Engineer-sdk/zephyr/dts/arm/st/h7/stm32h7.dtsi:680 */
			resets = < &rctl 0x1205 >;      /* in Engineer-sdk/zephyr/dts/arm/st/h7/stm32h7.dtsi:682 */
			interrupts = < 0x37 0x0 >;      /* in Engineer-sdk/zephyr/dts/arm/st/h7/stm32h7.dtsi:683 */
			interrupt-names = "global";     /* in Engineer-sdk/zephyr/dts/arm/st/h7/stm32h7.dtsi:684 */
			st,prescaler = < 0x0 >;         /* in Engineer-sdk/zephyr/dts/arm/st/h7/stm32h7.dtsi:685 */
			status = "disabled";            /* in Engineer-sdk/zephyr/dts/arm/st/h7/stm32h7.dtsi:686 */

			/* node '/soc/timers@40001400/counter' defined in Engineer-sdk/zephyr/dts/arm/st/h7/stm32h7.dtsi:688 */
			counter {
				compatible = "st,stm32-counter"; /* in Engineer-sdk/zephyr/dts/arm/st/h7/stm32h7.dtsi:689 */
				status = "disabled";             /* in Engineer-sdk/zephyr/dts/arm/st/h7/stm32h7.dtsi:690 */
			};
		};

		/* node '/soc/timers@40010400' defined in Engineer-sdk/zephyr/dts/arm/st/h7/stm32h7.dtsi:694 */
		timers8: timers@40010400 {
			compatible = "st,stm32-timers"; /* in Engineer-sdk/zephyr/dts/arm/st/h7/stm32h7.dtsi:695 */
			reg = < 0x40010400 0x400 >;     /* in Engineer-sdk/zephyr/dts/arm/st/h7/stm32h7.dtsi:696 */
			clocks = < &rcc 0xf0 0x2 >,
			         < &rcc 0x13 0xff >;    /* in Engineer-sdk/zephyr/dts/arm/st/h7/stm32h7.dtsi:697 */
			resets = < &rctl 0x1301 >;      /* in Engineer-sdk/zephyr/dts/arm/st/h7/stm32h7.dtsi:699 */
			interrupts = < 0x2b 0x0 >,
			             < 0x2c 0x0 >,
			             < 0x2d 0x0 >,
			             < 0x2e 0x0 >;      /* in Engineer-sdk/zephyr/dts/arm/st/h7/stm32h7.dtsi:700 */
			interrupt-names = "brk",
			                  "up",
			                  "trgcom",
			                  "cc";         /* in Engineer-sdk/zephyr/dts/arm/st/h7/stm32h7.dtsi:701 */
			st,prescaler = < 0x0 >;         /* in Engineer-sdk/zephyr/dts/arm/st/h7/stm32h7.dtsi:702 */
			status = "disabled";            /* in Engineer-sdk/zephyr/dts/arm/st/h7/stm32h7.dtsi:703 */

			/* node '/soc/timers@40010400/pwm' defined in Engineer-sdk/zephyr/dts/arm/st/h7/stm32h7.dtsi:705 */
			pwm {
				compatible = "st,stm32-pwm"; /* in Engineer-sdk/zephyr/dts/arm/st/h7/stm32h7.dtsi:706 */
				status = "disabled";         /* in Engineer-sdk/zephyr/dts/arm/st/h7/stm32h7.dtsi:707 */
				#pwm-cells = < 0x3 >;        /* in Engineer-sdk/zephyr/dts/arm/st/h7/stm32h7.dtsi:708 */
			};
		};

		/* node '/soc/timers@40001800' defined in Engineer-sdk/zephyr/dts/arm/st/h7/stm32h7.dtsi:712 */
		timers12: timers@40001800 {
			compatible = "st,stm32-timers"; /* in Engineer-sdk/zephyr/dts/arm/st/h7/stm32h7.dtsi:713 */
			reg = < 0x40001800 0x400 >;     /* in Engineer-sdk/zephyr/dts/arm/st/h7/stm32h7.dtsi:714 */
			clocks = < &rcc 0xe8 0x40 >,
			         < &rcc 0x12 0xff >;    /* in Engineer-sdk/zephyr/dts/arm/st/h7/stm32h7.dtsi:715 */
			resets = < &rctl 0x1206 >;      /* in Engineer-sdk/zephyr/dts/arm/st/h7/stm32h7.dtsi:717 */
			interrupts = < 0x2b 0x0 >;      /* in Engineer-sdk/zephyr/dts/arm/st/h7/stm32h7.dtsi:718 */
			interrupt-names = "global";     /* in Engineer-sdk/zephyr/dts/arm/st/h7/stm32h7.dtsi:719 */
			st,prescaler = < 0x0 >;         /* in Engineer-sdk/zephyr/dts/arm/st/h7/stm32h7.dtsi:720 */
			status = "disabled";            /* in Engineer-sdk/zephyr/dts/arm/st/h7/stm32h7.dtsi:721 */

			/* node '/soc/timers@40001800/pwm' defined in Engineer-sdk/zephyr/dts/arm/st/h7/stm32h7.dtsi:723 */
			pwm {
				compatible = "st,stm32-pwm"; /* in Engineer-sdk/zephyr/dts/arm/st/h7/stm32h7.dtsi:724 */
				status = "disabled";         /* in Engineer-sdk/zephyr/dts/arm/st/h7/stm32h7.dtsi:725 */
				#pwm-cells = < 0x3 >;        /* in Engineer-sdk/zephyr/dts/arm/st/h7/stm32h7.dtsi:726 */
			};

			/* node '/soc/timers@40001800/counter' defined in Engineer-sdk/zephyr/dts/arm/st/h7/stm32h7.dtsi:729 */
			counter {
				compatible = "st,stm32-counter"; /* in Engineer-sdk/zephyr/dts/arm/st/h7/stm32h7.dtsi:730 */
				status = "disabled";             /* in Engineer-sdk/zephyr/dts/arm/st/h7/stm32h7.dtsi:731 */
			};
		};

		/* node '/soc/timers@40001c00' defined in Engineer-sdk/zephyr/dts/arm/st/h7/stm32h7.dtsi:735 */
		timers13: timers@40001c00 {
			compatible = "st,stm32-timers"; /* in Engineer-sdk/zephyr/dts/arm/st/h7/stm32h7.dtsi:736 */
			reg = < 0x40001c00 0x400 >;     /* in Engineer-sdk/zephyr/dts/arm/st/h7/stm32h7.dtsi:737 */
			clocks = < &rcc 0xe8 0x80 >,
			         < &rcc 0x12 0xff >;    /* in Engineer-sdk/zephyr/dts/arm/st/h7/stm32h7.dtsi:738 */
			resets = < &rctl 0x1207 >;      /* in Engineer-sdk/zephyr/dts/arm/st/h7/stm32h7.dtsi:740 */
			interrupts = < 0x2c 0x0 >;      /* in Engineer-sdk/zephyr/dts/arm/st/h7/stm32h7.dtsi:741 */
			interrupt-names = "global";     /* in Engineer-sdk/zephyr/dts/arm/st/h7/stm32h7.dtsi:742 */
			st,prescaler = < 0x0 >;         /* in Engineer-sdk/zephyr/dts/arm/st/h7/stm32h7.dtsi:743 */
			status = "disabled";            /* in Engineer-sdk/zephyr/dts/arm/st/h7/stm32h7.dtsi:744 */

			/* node '/soc/timers@40001c00/pwm' defined in Engineer-sdk/zephyr/dts/arm/st/h7/stm32h7.dtsi:746 */
			pwm {
				compatible = "st,stm32-pwm"; /* in Engineer-sdk/zephyr/dts/arm/st/h7/stm32h7.dtsi:747 */
				status = "disabled";         /* in Engineer-sdk/zephyr/dts/arm/st/h7/stm32h7.dtsi:748 */
				#pwm-cells = < 0x3 >;        /* in Engineer-sdk/zephyr/dts/arm/st/h7/stm32h7.dtsi:749 */
			};

			/* node '/soc/timers@40001c00/counter' defined in Engineer-sdk/zephyr/dts/arm/st/h7/stm32h7.dtsi:752 */
			counter {
				compatible = "st,stm32-counter"; /* in Engineer-sdk/zephyr/dts/arm/st/h7/stm32h7.dtsi:753 */
				status = "disabled";             /* in Engineer-sdk/zephyr/dts/arm/st/h7/stm32h7.dtsi:754 */
			};
		};

		/* node '/soc/timers@40002000' defined in Engineer-sdk/zephyr/dts/arm/st/h7/stm32h7.dtsi:758 */
		timers14: timers@40002000 {
			compatible = "st,stm32-timers"; /* in Engineer-sdk/zephyr/dts/arm/st/h7/stm32h7.dtsi:759 */
			reg = < 0x40002000 0x400 >;     /* in Engineer-sdk/zephyr/dts/arm/st/h7/stm32h7.dtsi:760 */
			clocks = < &rcc 0xe8 0x100 >,
			         < &rcc 0x12 0xff >;    /* in Engineer-sdk/zephyr/dts/arm/st/h7/stm32h7.dtsi:761 */
			resets = < &rctl 0x1208 >;      /* in Engineer-sdk/zephyr/dts/arm/st/h7/stm32h7.dtsi:763 */
			interrupts = < 0x2d 0x0 >;      /* in Engineer-sdk/zephyr/dts/arm/st/h7/stm32h7.dtsi:764 */
			interrupt-names = "global";     /* in Engineer-sdk/zephyr/dts/arm/st/h7/stm32h7.dtsi:765 */
			st,prescaler = < 0x0 >;         /* in Engineer-sdk/zephyr/dts/arm/st/h7/stm32h7.dtsi:766 */
			status = "disabled";            /* in Engineer-sdk/zephyr/dts/arm/st/h7/stm32h7.dtsi:767 */

			/* node '/soc/timers@40002000/pwm' defined in Engineer-sdk/zephyr/dts/arm/st/h7/stm32h7.dtsi:769 */
			pwm {
				compatible = "st,stm32-pwm"; /* in Engineer-sdk/zephyr/dts/arm/st/h7/stm32h7.dtsi:770 */
				status = "disabled";         /* in Engineer-sdk/zephyr/dts/arm/st/h7/stm32h7.dtsi:771 */
				#pwm-cells = < 0x3 >;        /* in Engineer-sdk/zephyr/dts/arm/st/h7/stm32h7.dtsi:772 */
			};

			/* node '/soc/timers@40002000/counter' defined in Engineer-sdk/zephyr/dts/arm/st/h7/stm32h7.dtsi:775 */
			counter {
				compatible = "st,stm32-counter"; /* in Engineer-sdk/zephyr/dts/arm/st/h7/stm32h7.dtsi:776 */
				status = "disabled";             /* in Engineer-sdk/zephyr/dts/arm/st/h7/stm32h7.dtsi:777 */
			};
		};

		/* node '/soc/timers@40014000' defined in Engineer-sdk/zephyr/dts/arm/st/h7/stm32h7.dtsi:781 */
		timers15: timers@40014000 {
			compatible = "st,stm32-timers"; /* in Engineer-sdk/zephyr/dts/arm/st/h7/stm32h7.dtsi:782 */
			reg = < 0x40014000 0x400 >;     /* in Engineer-sdk/zephyr/dts/arm/st/h7/stm32h7.dtsi:783 */
			clocks = < &rcc 0xf0 0x10000 >,
			         < &rcc 0x13 0xff >;    /* in Engineer-sdk/zephyr/dts/arm/st/h7/stm32h7.dtsi:784 */
			resets = < &rctl 0x1310 >;      /* in Engineer-sdk/zephyr/dts/arm/st/h7/stm32h7.dtsi:786 */
			interrupts = < 0x74 0x0 >;      /* in Engineer-sdk/zephyr/dts/arm/st/h7/stm32h7.dtsi:787 */
			interrupt-names = "global";     /* in Engineer-sdk/zephyr/dts/arm/st/h7/stm32h7.dtsi:788 */
			st,prescaler = < 0x0 >;         /* in Engineer-sdk/zephyr/dts/arm/st/h7/stm32h7.dtsi:789 */
			status = "disabled";            /* in Engineer-sdk/zephyr/dts/arm/st/h7/stm32h7.dtsi:790 */

			/* node '/soc/timers@40014000/pwm' defined in Engineer-sdk/zephyr/dts/arm/st/h7/stm32h7.dtsi:792 */
			pwm {
				compatible = "st,stm32-pwm"; /* in Engineer-sdk/zephyr/dts/arm/st/h7/stm32h7.dtsi:793 */
				status = "disabled";         /* in Engineer-sdk/zephyr/dts/arm/st/h7/stm32h7.dtsi:794 */
				#pwm-cells = < 0x3 >;        /* in Engineer-sdk/zephyr/dts/arm/st/h7/stm32h7.dtsi:795 */
			};

			/* node '/soc/timers@40014000/counter' defined in Engineer-sdk/zephyr/dts/arm/st/h7/stm32h7.dtsi:798 */
			counter {
				compatible = "st,stm32-counter"; /* in Engineer-sdk/zephyr/dts/arm/st/h7/stm32h7.dtsi:799 */
				status = "disabled";             /* in Engineer-sdk/zephyr/dts/arm/st/h7/stm32h7.dtsi:800 */
			};
		};

		/* node '/soc/timers@40014400' defined in Engineer-sdk/zephyr/dts/arm/st/h7/stm32h7.dtsi:804 */
		timers16: timers@40014400 {
			compatible = "st,stm32-timers"; /* in Engineer-sdk/zephyr/dts/arm/st/h7/stm32h7.dtsi:805 */
			reg = < 0x40014400 0x400 >;     /* in Engineer-sdk/zephyr/dts/arm/st/h7/stm32h7.dtsi:806 */
			clocks = < &rcc 0xf0 0x20000 >,
			         < &rcc 0x13 0xff >;    /* in Engineer-sdk/zephyr/dts/arm/st/h7/stm32h7.dtsi:807 */
			resets = < &rctl 0x1311 >;      /* in Engineer-sdk/zephyr/dts/arm/st/h7/stm32h7.dtsi:809 */
			interrupts = < 0x75 0x0 >;      /* in Engineer-sdk/zephyr/dts/arm/st/h7/stm32h7.dtsi:810 */
			interrupt-names = "global";     /* in Engineer-sdk/zephyr/dts/arm/st/h7/stm32h7.dtsi:811 */
			st,prescaler = < 0x0 >;         /* in Engineer-sdk/zephyr/dts/arm/st/h7/stm32h7.dtsi:812 */
			status = "disabled";            /* in Engineer-sdk/zephyr/dts/arm/st/h7/stm32h7.dtsi:813 */

			/* node '/soc/timers@40014400/pwm' defined in Engineer-sdk/zephyr/dts/arm/st/h7/stm32h7.dtsi:815 */
			pwm {
				compatible = "st,stm32-pwm"; /* in Engineer-sdk/zephyr/dts/arm/st/h7/stm32h7.dtsi:816 */
				status = "disabled";         /* in Engineer-sdk/zephyr/dts/arm/st/h7/stm32h7.dtsi:817 */
				#pwm-cells = < 0x3 >;        /* in Engineer-sdk/zephyr/dts/arm/st/h7/stm32h7.dtsi:818 */
			};

			/* node '/soc/timers@40014400/counter' defined in Engineer-sdk/zephyr/dts/arm/st/h7/stm32h7.dtsi:821 */
			counter {
				compatible = "st,stm32-counter"; /* in Engineer-sdk/zephyr/dts/arm/st/h7/stm32h7.dtsi:822 */
				status = "disabled";             /* in Engineer-sdk/zephyr/dts/arm/st/h7/stm32h7.dtsi:823 */
			};
		};

		/* node '/soc/timers@40014800' defined in Engineer-sdk/zephyr/dts/arm/st/h7/stm32h7.dtsi:827 */
		timers17: timers@40014800 {
			compatible = "st,stm32-timers"; /* in Engineer-sdk/zephyr/dts/arm/st/h7/stm32h7.dtsi:828 */
			reg = < 0x40014800 0x400 >;     /* in Engineer-sdk/zephyr/dts/arm/st/h7/stm32h7.dtsi:829 */
			clocks = < &rcc 0xf0 0x40000 >,
			         < &rcc 0x13 0xff >;    /* in Engineer-sdk/zephyr/dts/arm/st/h7/stm32h7.dtsi:830 */
			resets = < &rctl 0x1312 >;      /* in Engineer-sdk/zephyr/dts/arm/st/h7/stm32h7.dtsi:832 */
			interrupts = < 0x76 0x0 >;      /* in Engineer-sdk/zephyr/dts/arm/st/h7/stm32h7.dtsi:833 */
			interrupt-names = "global";     /* in Engineer-sdk/zephyr/dts/arm/st/h7/stm32h7.dtsi:834 */
			st,prescaler = < 0x0 >;         /* in Engineer-sdk/zephyr/dts/arm/st/h7/stm32h7.dtsi:835 */
			status = "disabled";            /* in Engineer-sdk/zephyr/dts/arm/st/h7/stm32h7.dtsi:836 */

			/* node '/soc/timers@40014800/pwm' defined in Engineer-sdk/zephyr/dts/arm/st/h7/stm32h7.dtsi:838 */
			pwm {
				compatible = "st,stm32-pwm"; /* in Engineer-sdk/zephyr/dts/arm/st/h7/stm32h7.dtsi:839 */
				status = "disabled";         /* in Engineer-sdk/zephyr/dts/arm/st/h7/stm32h7.dtsi:840 */
				#pwm-cells = < 0x3 >;        /* in Engineer-sdk/zephyr/dts/arm/st/h7/stm32h7.dtsi:841 */
			};

			/* node '/soc/timers@40014800/counter' defined in Engineer-sdk/zephyr/dts/arm/st/h7/stm32h7.dtsi:844 */
			counter {
				compatible = "st,stm32-counter"; /* in Engineer-sdk/zephyr/dts/arm/st/h7/stm32h7.dtsi:845 */
				status = "disabled";             /* in Engineer-sdk/zephyr/dts/arm/st/h7/stm32h7.dtsi:846 */
			};
		};

		/* node '/soc/timers@40002400' defined in Engineer-sdk/zephyr/dts/arm/st/h7/stm32h7.dtsi:850 */
		lptim1: timers@40002400 {
			compatible = "st,stm32-lptim"; /* in Engineer-sdk/zephyr/dts/arm/st/h7/stm32h7.dtsi:851 */
			clocks = < &rcc 0xe8 0x200 >;  /* in Engineer-sdk/zephyr/dts/arm/st/h7/stm32h7.dtsi:852 */
			#address-cells = < 0x1 >;      /* in Engineer-sdk/zephyr/dts/arm/st/h7/stm32h7.dtsi:853 */
			#size-cells = < 0x0 >;         /* in Engineer-sdk/zephyr/dts/arm/st/h7/stm32h7.dtsi:854 */
			reg = < 0x40002400 0x400 >;    /* in Engineer-sdk/zephyr/dts/arm/st/h7/stm32h7.dtsi:855 */
			interrupts = < 0x5d 0x1 >;     /* in Engineer-sdk/zephyr/dts/arm/st/h7/stm32h7.dtsi:856 */
			interrupt-names = "wakeup";    /* in Engineer-sdk/zephyr/dts/arm/st/h7/stm32h7.dtsi:857 */
			status = "disabled";           /* in Engineer-sdk/zephyr/dts/arm/st/h7/stm32h7.dtsi:858 */
		};

		/* node '/soc/adc@40022000' defined in Engineer-sdk/zephyr/dts/arm/st/h7/stm32h7.dtsi:868 */
		adc1: adc@40022000 {
			compatible = "st,stm32-adc";                                    /* in Engineer-sdk/zephyr/dts/arm/st/h7/stm32h7.dtsi:869 */
			reg = < 0x40022000 0x400 >;                                     /* in Engineer-sdk/zephyr/dts/arm/st/h7/stm32h7.dtsi:870 */
			clocks = < &rcc 0xd8 0x20 >;                                    /* in Engineer-sdk/zephyr/dts/arm/st/h7/stm32h7.dtsi:871 */
			interrupts = < 0x12 0x0 >;                                      /* in Engineer-sdk/zephyr/dts/arm/st/h7/stm32h7.dtsi:872 */
			status = "disabled";                                            /* in Engineer-sdk/zephyr/dts/arm/st/h7/stm32h7.dtsi:873 */
			#io-channel-cells = < 0x1 >;                                    /* in Engineer-sdk/zephyr/dts/arm/st/h7/stm32h7.dtsi:874 */
			resolutions = < 0x80e20c 0x75e20c 0x66e20c 0x53e20c 0x47e20c >; /* in Engineer-sdk/zephyr/dts/arm/st/h7/stm32h7.dtsi:875 */
			sampling-times = < 0x2 0x3 0x9 0x11 0x21 0x41 0x184 0x32b >;    /* in Engineer-sdk/zephyr/dts/arm/st/h7/stm32h7.dtsi:880 */
			st,adc-sequencer = "FULLY_CONFIGURABLE";                        /* in Engineer-sdk/zephyr/dts/arm/st/h7/stm32h7.dtsi:881 */
			st,adc-oversampler = "OVERSAMPLER_EXTENDED";                    /* in Engineer-sdk/zephyr/dts/arm/st/h7/stm32h7.dtsi:882 */
		};

		/* node '/soc/adc@40022100' defined in Engineer-sdk/zephyr/dts/arm/st/h7/stm32h7.dtsi:885 */
		adc2: adc@40022100 {
			compatible = "st,stm32-adc";                                    /* in Engineer-sdk/zephyr/dts/arm/st/h7/stm32h7.dtsi:886 */
			reg = < 0x40022100 0x400 >;                                     /* in Engineer-sdk/zephyr/dts/arm/st/h7/stm32h7.dtsi:887 */
			clocks = < &rcc 0xd8 0x20 >;                                    /* in Engineer-sdk/zephyr/dts/arm/st/h7/stm32h7.dtsi:888 */
			interrupts = < 0x12 0x0 >;                                      /* in Engineer-sdk/zephyr/dts/arm/st/h7/stm32h7.dtsi:889 */
			status = "disabled";                                            /* in Engineer-sdk/zephyr/dts/arm/st/h7/stm32h7.dtsi:890 */
			#io-channel-cells = < 0x1 >;                                    /* in Engineer-sdk/zephyr/dts/arm/st/h7/stm32h7.dtsi:891 */
			resolutions = < 0x80e20c 0x75e20c 0x66e20c 0x53e20c 0x47e20c >; /* in Engineer-sdk/zephyr/dts/arm/st/h7/stm32h7.dtsi:892 */
			sampling-times = < 0x2 0x3 0x9 0x11 0x21 0x41 0x184 0x32b >;    /* in Engineer-sdk/zephyr/dts/arm/st/h7/stm32h7.dtsi:897 */
			st,adc-sequencer = "FULLY_CONFIGURABLE";                        /* in Engineer-sdk/zephyr/dts/arm/st/h7/stm32h7.dtsi:898 */
			st,adc-oversampler = "OVERSAMPLER_EXTENDED";                    /* in Engineer-sdk/zephyr/dts/arm/st/h7/stm32h7.dtsi:899 */
		};

		/* node '/soc/adc@40022300' defined in Engineer-sdk/zephyr/dts/arm/st/h7/stm32h7.dtsi:903 */
		adc1_2: adc@40022300 {
			compatible = "st,stm32-adc";                                    /* in Engineer-sdk/zephyr/dts/arm/st/h7/stm32h7.dtsi:904 */
			reg = < 0x40022300 0x400 >;                                     /* in Engineer-sdk/zephyr/dts/arm/st/h7/stm32h7.dtsi:905 */
			clocks = < &rcc 0xd8 0x20 >;                                    /* in Engineer-sdk/zephyr/dts/arm/st/h7/stm32h7.dtsi:906 */
			interrupts = < 0x12 0x0 >;                                      /* in Engineer-sdk/zephyr/dts/arm/st/h7/stm32h7.dtsi:907 */
			status = "disabled";                                            /* in Engineer-sdk/zephyr/dts/arm/st/h7/stm32h7.dtsi:908 */
			#io-channel-cells = < 0x1 >;                                    /* in Engineer-sdk/zephyr/dts/arm/st/h7/stm32h7.dtsi:909 */
			resolutions = < 0x80e20c 0x75e20c 0x66e20c 0x53e20c 0x47e20c >; /* in Engineer-sdk/zephyr/dts/arm/st/h7/stm32h7.dtsi:910 */
			sampling-times = < 0x2 0x3 0x9 0x11 0x21 0x41 0x184 0x32b >;    /* in Engineer-sdk/zephyr/dts/arm/st/h7/stm32h7.dtsi:915 */
			st,adc-sequencer = "FULLY_CONFIGURABLE";                        /* in Engineer-sdk/zephyr/dts/arm/st/h7/stm32h7.dtsi:916 */
			st,adc-oversampler = "OVERSAMPLER_EXTENDED";                    /* in Engineer-sdk/zephyr/dts/arm/st/h7/stm32h7.dtsi:917 */
		};

		/* node '/soc/adc@58026000' defined in Engineer-sdk/zephyr/dts/arm/st/h7/stm32h7.dtsi:920 */
		adc3: adc@58026000 {
			compatible = "st,stm32-adc";                                /* in Engineer-sdk/zephyr/dts/arm/st/h7/stm32h7.dtsi:921 */
			reg = < 0x58026000 0x400 >;                                 /* in Engineer-sdk/zephyr/dts/arm/st/h7/stm32h7.dtsi:922 */
			clocks = < &rcc 0xe0 0x1000000 >;                           /* in Engineer-sdk/zephyr/dts/arm/st/h7/stm32h7.dtsi:923 */
			interrupts = < 0x7f 0x0 >;                                  /* in Engineer-sdk/zephyr/dts/arm/st/h7/stm32h7.dtsi:924 */
			status = "disabled";                                        /* in Engineer-sdk/zephyr/dts/arm/st/h7/stm32h7.dtsi:925 */
			#io-channel-cells = < 0x1 >;                                /* in Engineer-sdk/zephyr/dts/arm/st/h7/stm32h7.dtsi:926 */
			resolutions = < 0x60630c 0x51630c 0x42630c 0x33630c >;      /* in Engineer-sdk/zephyr/dts/arm/st/h7/stm32h723.dtsi:50 */
			sampling-times = < 0x3 0x7 0xd 0x19 0x30 0x5d 0xf8 0x281 >; /* in Engineer-sdk/zephyr/dts/arm/st/h7/stm32h723.dtsi:54 */
			st,adc-sequencer = "FULLY_CONFIGURABLE";                    /* in Engineer-sdk/zephyr/dts/arm/st/h7/stm32h723.dtsi:55 */
			st,adc-oversampler = "OVERSAMPLER_MINIMAL";                 /* in Engineer-sdk/zephyr/dts/arm/st/h7/stm32h723.dtsi:56 */
			phandle = < 0x25 >;                                         /* in Engineer-sdk/zephyr/dts/arm/st/h7/stm32h723.dtsi:242 */
		};

		/* node '/soc/dac@40007400' defined in Engineer-sdk/zephyr/dts/arm/st/h7/stm32h7.dtsi:937 */
		dac1: dac@40007400 {
			compatible = "st,stm32-dac";       /* in Engineer-sdk/zephyr/dts/arm/st/h7/stm32h7.dtsi:938 */
			reg = < 0x40007400 0x400 >;        /* in Engineer-sdk/zephyr/dts/arm/st/h7/stm32h7.dtsi:939 */
			clocks = < &rcc 0xe8 0x20000000 >; /* in Engineer-sdk/zephyr/dts/arm/st/h7/stm32h7.dtsi:940 */
			status = "disabled";               /* in Engineer-sdk/zephyr/dts/arm/st/h7/stm32h7.dtsi:941 */
			#io-channel-cells = < 0x1 >;       /* in Engineer-sdk/zephyr/dts/arm/st/h7/stm32h7.dtsi:942 */
		};

		/* node '/soc/dma@40020000' defined in Engineer-sdk/zephyr/dts/arm/st/h7/stm32h7.dtsi:945 */
		dma1: dma@40020000 {
			compatible = "st,stm32-dma-v1"; /* in Engineer-sdk/zephyr/dts/arm/st/h7/stm32h7.dtsi:946 */
			#dma-cells = < 0x4 >;           /* in Engineer-sdk/zephyr/dts/arm/st/h7/stm32h7.dtsi:947 */
			reg = < 0x40020000 0x400 >;     /* in Engineer-sdk/zephyr/dts/arm/st/h7/stm32h7.dtsi:948 */
			interrupts = < 0xb 0x0 >,
			             < 0xc 0x0 >,
			             < 0xd 0x0 >,
			             < 0xe 0x0 >,
			             < 0xf 0x0 >,
			             < 0x10 0x0 >,
			             < 0x11 0x0 >,
			             < 0x2f 0x0 >;      /* in Engineer-sdk/zephyr/dts/arm/st/h7/stm32h7.dtsi:949 */
			clocks = < &rcc 0xd8 0x1 >;     /* in Engineer-sdk/zephyr/dts/arm/st/h7/stm32h7.dtsi:951 */
			st,mem2mem;                     /* in Engineer-sdk/zephyr/dts/arm/st/h7/stm32h7.dtsi:952 */
			dma-offset = < 0x0 >;           /* in Engineer-sdk/zephyr/dts/arm/st/h7/stm32h7.dtsi:953 */
			dma-requests = < 0x8 >;         /* in Engineer-sdk/zephyr/dts/arm/st/h7/stm32h7.dtsi:954 */
			status = "okay";                /* in Engineer-manifest/boards/damiao/mc02/damiao_mc02.dts:116 */
			dma-channels = < 0x8 >;         /* in Engineer-manifest/boards/damiao/mc02/damiao_mc02.dts:117 */
			phandle = < 0x1e >;             /* in Engineer-sdk/zephyr/dts/arm/st/h7/stm32h7.dtsi:1105 */
		};

		/* node '/soc/dma@40020400' defined in Engineer-sdk/zephyr/dts/arm/st/h7/stm32h7.dtsi:958 */
		dma2: dma@40020400 {
			compatible = "st,stm32-dma-v1"; /* in Engineer-sdk/zephyr/dts/arm/st/h7/stm32h7.dtsi:959 */
			#dma-cells = < 0x4 >;           /* in Engineer-sdk/zephyr/dts/arm/st/h7/stm32h7.dtsi:960 */
			reg = < 0x40020400 0x400 >;     /* in Engineer-sdk/zephyr/dts/arm/st/h7/stm32h7.dtsi:961 */
			interrupts = < 0x38 0x0 >,
			             < 0x39 0x0 >,
			             < 0x3a 0x0 >,
			             < 0x3b 0x0 >,
			             < 0x3c 0x0 >,
			             < 0x44 0x0 >,
			             < 0x45 0x0 >,
			             < 0x46 0x0 >;      /* in Engineer-sdk/zephyr/dts/arm/st/h7/stm32h7.dtsi:962 */
			clocks = < &rcc 0xd8 0x2 >;     /* in Engineer-sdk/zephyr/dts/arm/st/h7/stm32h7.dtsi:964 */
			st,mem2mem;                     /* in Engineer-sdk/zephyr/dts/arm/st/h7/stm32h7.dtsi:965 */
			dma-offset = < 0x8 >;           /* in Engineer-sdk/zephyr/dts/arm/st/h7/stm32h7.dtsi:966 */
			dma-requests = < 0x8 >;         /* in Engineer-sdk/zephyr/dts/arm/st/h7/stm32h7.dtsi:967 */
			status = "okay";                /* in Engineer-manifest/boards/damiao/mc02/damiao_mc02.dts:121 */
			dma-channels = < 0x8 >;         /* in Engineer-manifest/boards/damiao/mc02/damiao_mc02.dts:122 */
		};

		/* node '/soc/bdma@58025400' defined in Engineer-sdk/zephyr/dts/arm/st/h7/stm32h7.dtsi:971 */
		bdma1: bdma@58025400 {
			compatible = "st,stm32-bdma";    /* in Engineer-sdk/zephyr/dts/arm/st/h7/stm32h7.dtsi:972 */
			#dma-cells = < 0x4 >;            /* in Engineer-sdk/zephyr/dts/arm/st/h7/stm32h7.dtsi:973 */
			reg = < 0x58025400 0x400 >;      /* in Engineer-sdk/zephyr/dts/arm/st/h7/stm32h7.dtsi:974 */
			interrupts = < 0x81 0x0 >,
			             < 0x82 0x0 >,
			             < 0x83 0x0 >,
			             < 0x84 0x0 >,
			             < 0x85 0x0 >,
			             < 0x86 0x0 >,
			             < 0x87 0x0 >,
			             < 0x88 0x0 >;       /* in Engineer-sdk/zephyr/dts/arm/st/h7/stm32h7.dtsi:975 */
			clocks = < &rcc 0xe0 0x200000 >; /* in Engineer-sdk/zephyr/dts/arm/st/h7/stm32h7.dtsi:977 */
			st,mem2mem;                      /* in Engineer-sdk/zephyr/dts/arm/st/h7/stm32h7.dtsi:978 */
			dma-offset = < 0x0 >;            /* in Engineer-sdk/zephyr/dts/arm/st/h7/stm32h7.dtsi:979 */
			dma-requests = < 0x8 >;          /* in Engineer-sdk/zephyr/dts/arm/st/h7/stm32h7.dtsi:980 */
			status = "disabled";             /* in Engineer-sdk/zephyr/dts/arm/st/h7/stm32h7.dtsi:981 */
		};

		/* node '/soc/dmamux@40020800' defined in Engineer-sdk/zephyr/dts/arm/st/h7/stm32h7.dtsi:984 */
		dmamux1: dmamux@40020800 {
			compatible = "st,stm32-dmamux"; /* in Engineer-sdk/zephyr/dts/arm/st/h7/stm32h7.dtsi:985 */
			#dma-cells = < 0x3 >;           /* in Engineer-sdk/zephyr/dts/arm/st/h7/stm32h7.dtsi:986 */
			reg = < 0x40020800 0x400 >;     /* in Engineer-sdk/zephyr/dts/arm/st/h7/stm32h7.dtsi:987 */
			interrupts = < 0x66 0x0 >;      /* in Engineer-sdk/zephyr/dts/arm/st/h7/stm32h7.dtsi:988 */
			clocks = < &rcc 0xd8 0x1 >;     /* in Engineer-sdk/zephyr/dts/arm/st/h7/stm32h7.dtsi:990 */
			dma-channels = < 0x10 >;        /* in Engineer-sdk/zephyr/dts/arm/st/h7/stm32h7.dtsi:991 */
			dma-generators = < 0x8 >;       /* in Engineer-sdk/zephyr/dts/arm/st/h7/stm32h7.dtsi:992 */
			dma-requests = < 0x81 >;        /* in Engineer-sdk/zephyr/dts/arm/st/h7/stm32h723.dtsi:60 */
			status = "okay";                /* in Engineer-manifest/boards/damiao/mc02/damiao_mc02.dts:132 */
			phandle = < 0x7 >;              /* in Engineer-manifest/boards/damiao/mc02/damiao_mc02.dts:222 */
		};

		/* node '/soc/dmamux@58025800' defined in Engineer-sdk/zephyr/dts/arm/st/h7/stm32h7.dtsi:1000 */
		dmamux2: dmamux@58025800 {
			compatible = "st,stm32-dmamux";  /* in Engineer-sdk/zephyr/dts/arm/st/h7/stm32h7.dtsi:1001 */
			#dma-cells = < 0x3 >;            /* in Engineer-sdk/zephyr/dts/arm/st/h7/stm32h7.dtsi:1002 */
			reg = < 0x58025800 0x400 >;      /* in Engineer-sdk/zephyr/dts/arm/st/h7/stm32h7.dtsi:1003 */
			interrupts = < 0x80 0x0 >;       /* in Engineer-sdk/zephyr/dts/arm/st/h7/stm32h7.dtsi:1004 */
			clocks = < &rcc 0xe0 0x200000 >; /* in Engineer-sdk/zephyr/dts/arm/st/h7/stm32h7.dtsi:1006 */
			dma-channels = < 0x8 >;          /* in Engineer-sdk/zephyr/dts/arm/st/h7/stm32h7.dtsi:1007 */
			dma-generators = < 0x8 >;        /* in Engineer-sdk/zephyr/dts/arm/st/h7/stm32h7.dtsi:1008 */
			status = "disabled";             /* in Engineer-sdk/zephyr/dts/arm/st/h7/stm32h7.dtsi:1009 */
			dma-requests = < 0x81 >;         /* in Engineer-sdk/zephyr/dts/arm/st/h7/stm32h723.dtsi:64 */
		};

		/* node '/soc/rng@48021800' defined in Engineer-sdk/zephyr/dts/arm/st/h7/stm32h7.dtsi:1016 */
		rng: rng@48021800 {
			compatible = "st,stm32-rng";        /* in Engineer-sdk/zephyr/dts/arm/st/h7/stm32h7.dtsi:1017 */
			reg = < 0x48021800 0x400 >;         /* in Engineer-sdk/zephyr/dts/arm/st/h7/stm32h7.dtsi:1018 */
			clocks = < &rcc 0xdc 0x40 >;        /* in Engineer-sdk/zephyr/dts/arm/st/h7/stm32h7.dtsi:1019 */
			interrupts = < 0x50 0x0 >;          /* in Engineer-sdk/zephyr/dts/arm/st/h7/stm32h7.dtsi:1020 */
			status = "disabled";                /* in Engineer-sdk/zephyr/dts/arm/st/h7/stm32h7.dtsi:1021 */
			health-test-magic = < 0x17590abc >; /* in Engineer-sdk/zephyr/dts/arm/st/h7/stm32h723.dtsi:68 */
			health-test-config = < 0xaa74 >;    /* in Engineer-sdk/zephyr/dts/arm/st/h7/stm32h723.dtsi:69 */
		};

		/* node '/soc/sdmmc@52007000' defined in Engineer-sdk/zephyr/dts/arm/st/h7/stm32h7.dtsi:1024 */
		sdmmc1: sdmmc@52007000 {
			compatible = "st,stm32-sdmmc";  /* in Engineer-sdk/zephyr/dts/arm/st/h7/stm32h7.dtsi:1025 */
			reg = < 0x52007000 0x400 >;     /* in Engineer-sdk/zephyr/dts/arm/st/h7/stm32h7.dtsi:1026 */
			clocks = < &rcc 0xd4 0x10000 >,
			         < &rcc 0x9 0x50004c >; /* in Engineer-sdk/zephyr/dts/arm/st/h7/stm32h7.dtsi:1027 */
			resets = < &rctl 0xf90 >;       /* in Engineer-sdk/zephyr/dts/arm/st/h7/stm32h7.dtsi:1029 */
			interrupts = < 0x31 0x0 >;      /* in Engineer-sdk/zephyr/dts/arm/st/h7/stm32h7.dtsi:1030 */
			status = "disabled";            /* in Engineer-sdk/zephyr/dts/arm/st/h7/stm32h7.dtsi:1031 */
		};

		/* node '/soc/sdmmc@48022400' defined in Engineer-sdk/zephyr/dts/arm/st/h7/stm32h7.dtsi:1034 */
		sdmmc2: sdmmc@48022400 {
			compatible = "st,stm32-sdmmc";  /* in Engineer-sdk/zephyr/dts/arm/st/h7/stm32h7.dtsi:1035 */
			reg = < 0x48022400 0x400 >;     /* in Engineer-sdk/zephyr/dts/arm/st/h7/stm32h7.dtsi:1036 */
			clocks = < &rcc 0xdc 0x200 >,
			         < &rcc 0x9 0x50004c >; /* in Engineer-sdk/zephyr/dts/arm/st/h7/stm32h7.dtsi:1037 */
			resets = < &rctl 0x1089 >;      /* in Engineer-sdk/zephyr/dts/arm/st/h7/stm32h7.dtsi:1039 */
			interrupts = < 0x7c 0x0 >;      /* in Engineer-sdk/zephyr/dts/arm/st/h7/stm32h7.dtsi:1040 */
			status = "disabled";            /* in Engineer-sdk/zephyr/dts/arm/st/h7/stm32h7.dtsi:1041 */
		};

		/* node '/soc/ethernet@40028000' defined in Engineer-sdk/zephyr/dts/arm/st/h7/stm32h7.dtsi:1044 */
		ethernet@40028000 {
			reg = < 0x40028000 0x8000 >;                 /* in Engineer-sdk/zephyr/dts/arm/st/h7/stm32h7.dtsi:1045 */
			compatible = "st,stm32-ethernet-controller"; /* in Engineer-sdk/zephyr/dts/arm/st/h7/stm32h7.dtsi:1046 */
			clock-names = "stm-eth";                     /* in Engineer-sdk/zephyr/dts/arm/st/h7/stm32h7.dtsi:1047 */
			clocks = < &rcc 0xd8 0x8000 >;               /* in Engineer-sdk/zephyr/dts/arm/st/h7/stm32h7.dtsi:1048 */

			/* node '/soc/ethernet@40028000/ethernet' defined in Engineer-sdk/zephyr/dts/arm/st/h7/stm32h7.dtsi:1050 */
			mac: ethernet {
				compatible = "st,stm32h7-ethernet",
				             "st,stm32-ethernet";   /* in Engineer-sdk/zephyr/dts/arm/st/h7/stm32h7.dtsi:1051 */
				interrupts = < 0x3d 0x0 >;          /* in Engineer-sdk/zephyr/dts/arm/st/h7/stm32h7.dtsi:1052 */
				clock-names = "mac-clk-tx",
				              "mac-clk-rx";         /* in Engineer-sdk/zephyr/dts/arm/st/h7/stm32h7.dtsi:1053 */
				clocks = < &rcc 0xd8 0x10000 >,
				         < &rcc 0xd8 0x20000 >;     /* in Engineer-sdk/zephyr/dts/arm/st/h7/stm32h7.dtsi:1054 */
				status = "disabled";                /* in Engineer-sdk/zephyr/dts/arm/st/h7/stm32h7.dtsi:1056 */
			};

			/* node '/soc/ethernet@40028000/mdio' defined in Engineer-sdk/zephyr/dts/arm/st/h7/stm32h7.dtsi:1059 */
			mdio: mdio {
				compatible = "st,stm32-mdio"; /* in Engineer-sdk/zephyr/dts/arm/st/h7/stm32h7.dtsi:1060 */
				#address-cells = < 0x1 >;     /* in Engineer-sdk/zephyr/dts/arm/st/h7/stm32h7.dtsi:1061 */
				#size-cells = < 0x0 >;        /* in Engineer-sdk/zephyr/dts/arm/st/h7/stm32h7.dtsi:1062 */
				status = "disabled";          /* in Engineer-sdk/zephyr/dts/arm/st/h7/stm32h7.dtsi:1063 */
			};
		};

		/* node '/soc/memory-controller@52004000' defined in Engineer-sdk/zephyr/dts/arm/st/h7/stm32h7.dtsi:1067 */
		fmc: memory-controller@52004000 {
			compatible = "st,stm32h7-fmc"; /* in Engineer-sdk/zephyr/dts/arm/st/h7/stm32h7.dtsi:1068 */
			reg = < 0x52004000 0x400 >;    /* in Engineer-sdk/zephyr/dts/arm/st/h7/stm32h7.dtsi:1069 */
			clocks = < &rcc 0xd4 0x1000 >; /* in Engineer-sdk/zephyr/dts/arm/st/h7/stm32h7.dtsi:1070 */
			status = "disabled";           /* in Engineer-sdk/zephyr/dts/arm/st/h7/stm32h7.dtsi:1071 */

			/* node '/soc/memory-controller@52004000/sdram' defined in Engineer-sdk/zephyr/dts/arm/st/h7/stm32h7.dtsi:1073 */
			sdram: sdram {
				compatible = "st,stm32-fmc-sdram"; /* in Engineer-sdk/zephyr/dts/arm/st/h7/stm32h7.dtsi:1074 */
				#address-cells = < 0x1 >;          /* in Engineer-sdk/zephyr/dts/arm/st/h7/stm32h7.dtsi:1075 */
				#size-cells = < 0x0 >;             /* in Engineer-sdk/zephyr/dts/arm/st/h7/stm32h7.dtsi:1076 */
				status = "disabled";               /* in Engineer-sdk/zephyr/dts/arm/st/h7/stm32h7.dtsi:1077 */
			};
		};

		/* node '/soc/memory@38800000' defined in Engineer-sdk/zephyr/dts/arm/st/h7/stm32h7.dtsi:1081 */
		backup_sram: memory@38800000 {
			compatible = "zephyr,memory-region",
			             "st,stm32-backup-sram";  /* in Engineer-sdk/zephyr/dts/arm/st/h7/stm32h7.dtsi:1082 */
			reg = < 0x38800000 0x1000 >;          /* in Engineer-sdk/zephyr/dts/arm/st/h7/stm32h7.dtsi:1083 */
			clocks = < &rcc 0xe0 0x10000000 >;    /* in Engineer-sdk/zephyr/dts/arm/st/h7/stm32h7.dtsi:1084 */
			zephyr,memory-region = "BACKUP_SRAM"; /* in Engineer-sdk/zephyr/dts/arm/st/h7/stm32h7.dtsi:1085 */
			status = "okay";                      /* in Engineer-manifest/boards/damiao/mc02/damiao_mc02.dts:112 */
		};

		/* node '/soc/spi@52005000' defined in Engineer-sdk/zephyr/dts/arm/st/h7/stm32h7.dtsi:1089 */
		quadspi: octospi1: spi@52005000 {
			compatible = "st,stm32-ospi";    /* in Engineer-sdk/zephyr/dts/arm/st/h7/stm32h723.dtsi:97 */
			reg = < 0x52005000 0x1000 >,
			      < 0x90000000 0x10000000 >; /* in Engineer-sdk/zephyr/dts/arm/st/h7/stm32h723.dtsi:98 */
			interrupts = < 0x5c 0x0 >;       /* in Engineer-sdk/zephyr/dts/arm/st/h7/stm32h723.dtsi:99 */
			clock-names = "ospix",
			              "ospi-ker";        /* in Engineer-sdk/zephyr/dts/arm/st/h7/stm32h723.dtsi:100 */
			clocks = < &rcc 0xd4 0x4000 >,
			         < &rcc 0x9 0x8c4004c >; /* in Engineer-sdk/zephyr/dts/arm/st/h7/stm32h723.dtsi:101 */
			#address-cells = < 0x1 >;        /* in Engineer-sdk/zephyr/dts/arm/st/h7/stm32h723.dtsi:103 */
			#size-cells = < 0x0 >;           /* in Engineer-sdk/zephyr/dts/arm/st/h7/stm32h723.dtsi:104 */
			status = "disabled";             /* in Engineer-sdk/zephyr/dts/arm/st/h7/stm32h723.dtsi:105 */
		};

		/* node '/soc/dcmi@48020000' defined in Engineer-sdk/zephyr/dts/arm/st/h7/stm32h7.dtsi:1099 */
		dcmi: dcmi@48020000 {
			compatible = "st,stm32-dcmi";          /* in Engineer-sdk/zephyr/dts/arm/st/h7/stm32h7.dtsi:1100 */
			reg = < 0x48020000 0x400 >;            /* in Engineer-sdk/zephyr/dts/arm/st/h7/stm32h7.dtsi:1101 */
			interrupts = < 0x4e 0x0 >;             /* in Engineer-sdk/zephyr/dts/arm/st/h7/stm32h7.dtsi:1102 */
			interrupt-names = "dcmi";              /* in Engineer-sdk/zephyr/dts/arm/st/h7/stm32h7.dtsi:1103 */
			clocks = < &rcc 0xdc 0x1 >;            /* in Engineer-sdk/zephyr/dts/arm/st/h7/stm32h7.dtsi:1104 */
			dmas = < &dma1 0x0 0x4b 0x24480 0x0 >; /* in Engineer-sdk/zephyr/dts/arm/st/h7/stm32h7.dtsi:1105 */
			status = "disabled";                   /* in Engineer-sdk/zephyr/dts/arm/st/h7/stm32h7.dtsi:1108 */
		};

		/* node '/soc/sai1@40015804' defined in Engineer-sdk/zephyr/dts/arm/st/h7/stm32h7.dtsi:1111 */
		sai1_a: sai1@40015804 {
			compatible = "st,stm32-sai";           /* in Engineer-sdk/zephyr/dts/arm/st/h7/stm32h7.dtsi:1112 */
			#address-cells = < 0x1 >;              /* in Engineer-sdk/zephyr/dts/arm/st/h7/stm32h7.dtsi:1113 */
			#size-cells = < 0x0 >;                 /* in Engineer-sdk/zephyr/dts/arm/st/h7/stm32h7.dtsi:1114 */
			reg = < 0x40015804 0x20 >;             /* in Engineer-sdk/zephyr/dts/arm/st/h7/stm32h7.dtsi:1115 */
			clocks = < &rcc 0xf0 0x400000 >,
			         < &rcc 0xb 0x9c00050 >;       /* in Engineer-sdk/zephyr/dts/arm/st/h7/stm32h7.dtsi:1116 */
			dmas = < &dma1 0x1 0x57 0x22800 0x0 >; /* in Engineer-sdk/zephyr/dts/arm/st/h7/stm32h7.dtsi:1118 */
			status = "disabled";                   /* in Engineer-sdk/zephyr/dts/arm/st/h7/stm32h7.dtsi:1120 */
		};

		/* node '/soc/sai1@40015824' defined in Engineer-sdk/zephyr/dts/arm/st/h7/stm32h7.dtsi:1123 */
		sai1_b: sai1@40015824 {
			compatible = "st,stm32-sai";           /* in Engineer-sdk/zephyr/dts/arm/st/h7/stm32h7.dtsi:1124 */
			#address-cells = < 0x1 >;              /* in Engineer-sdk/zephyr/dts/arm/st/h7/stm32h7.dtsi:1125 */
			#size-cells = < 0x0 >;                 /* in Engineer-sdk/zephyr/dts/arm/st/h7/stm32h7.dtsi:1126 */
			reg = < 0x40015824 0x20 >;             /* in Engineer-sdk/zephyr/dts/arm/st/h7/stm32h7.dtsi:1127 */
			clocks = < &rcc 0xf0 0x400000 >,
			         < &rcc 0xb 0x9c00050 >;       /* in Engineer-sdk/zephyr/dts/arm/st/h7/stm32h7.dtsi:1128 */
			dmas = < &dma1 0x0 0x58 0x22800 0x0 >; /* in Engineer-sdk/zephyr/dts/arm/st/h7/stm32h7.dtsi:1130 */
			status = "disabled";                   /* in Engineer-sdk/zephyr/dts/arm/st/h7/stm32h7.dtsi:1132 */
		};

		/* node '/soc/serial@40011800' defined in Engineer-sdk/zephyr/dts/arm/st/h7/stm32h723.dtsi:27 */
		uart9: serial@40011800 {
			compatible = "st,stm32-uart"; /* in Engineer-sdk/zephyr/dts/arm/st/h7/stm32h723.dtsi:28 */
			reg = < 0x40011800 0x400 >;   /* in Engineer-sdk/zephyr/dts/arm/st/h7/stm32h723.dtsi:29 */
			clocks = < &rcc 0xf0 0x40 >;  /* in Engineer-sdk/zephyr/dts/arm/st/h7/stm32h723.dtsi:30 */
			resets = < &rctl 0x1306 >;    /* in Engineer-sdk/zephyr/dts/arm/st/h7/stm32h723.dtsi:31 */
			interrupts = < 0x9b 0x0 >;    /* in Engineer-sdk/zephyr/dts/arm/st/h7/stm32h723.dtsi:32 */
			status = "disabled";          /* in Engineer-sdk/zephyr/dts/arm/st/h7/stm32h723.dtsi:33 */
		};

		/* node '/soc/serial@40011c00' defined in Engineer-sdk/zephyr/dts/arm/st/h7/stm32h723.dtsi:36 */
		usart10: serial@40011c00 {
			compatible = "st,stm32-usart",
			             "st,stm32-uart";                    /* in Engineer-sdk/zephyr/dts/arm/st/h7/stm32h723.dtsi:37 */
			reg = < 0x40011c00 0x400 >;                      /* in Engineer-sdk/zephyr/dts/arm/st/h7/stm32h723.dtsi:38 */
			clocks = < &rcc 0xf0 0x80 >;                     /* in Engineer-sdk/zephyr/dts/arm/st/h7/stm32h723.dtsi:39 */
			resets = < &rctl 0x1307 >;                       /* in Engineer-sdk/zephyr/dts/arm/st/h7/stm32h723.dtsi:40 */
			interrupts = < 0x9c 0x0 >;                       /* in Engineer-sdk/zephyr/dts/arm/st/h7/stm32h723.dtsi:41 */
			status = "okay";                                 /* in Engineer-manifest/boards/damiao/mc02/damiao_mc02.dts:240 */
			current-speed = < 0x1c200 >;                     /* in Engineer-manifest/boards/damiao/mc02/damiao_mc02.dts:241 */
			stop-bits = "1";                                 /* in Engineer-manifest/boards/damiao/mc02/damiao_mc02.dts:242 */
			data-bits = < 0x8 >;                             /* in Engineer-manifest/boards/damiao/mc02/damiao_mc02.dts:243 */
			parity = "none";                                 /* in Engineer-manifest/boards/damiao/mc02/damiao_mc02.dts:244 */
			pinctrl-0 = < &usart10_tx_pe3 &usart10_rx_pe2 >; /* in Engineer-manifest/boards/damiao/mc02/damiao_mc02.dts:245 */
			pinctrl-names = "default";                       /* in Engineer-manifest/boards/damiao/mc02/damiao_mc02.dts:246 */
			fifo-enable;                                     /* in Engineer-manifest/boards/damiao/mc02/damiao_mc02.dts:247 */
		};

		/* node '/soc/usb@40040000' defined in Engineer-sdk/zephyr/dts/arm/st/h7/stm32h723.dtsi:72 */
		usbotg_hs: usb@40040000 {
			compatible = "st,stm32-otghs";    /* in Engineer-sdk/zephyr/dts/arm/st/h7/stm32h723.dtsi:73 */
			reg = < 0x40040000 0x40000 >;     /* in Engineer-sdk/zephyr/dts/arm/st/h7/stm32h723.dtsi:74 */
			interrupts = < 0x4d 0x0 >,
			             < 0x4a 0x0 >,
			             < 0x4b 0x0 >;        /* in Engineer-sdk/zephyr/dts/arm/st/h7/stm32h723.dtsi:75 */
			interrupt-names = "otghs",
			                  "ep1_out",
			                  "ep1_in";       /* in Engineer-sdk/zephyr/dts/arm/st/h7/stm32h723.dtsi:76 */
			num-bidir-endpoints = < 0x9 >;    /* in Engineer-sdk/zephyr/dts/arm/st/h7/stm32h723.dtsi:77 */
			ram-size = < 0x1000 >;            /* in Engineer-sdk/zephyr/dts/arm/st/h7/stm32h723.dtsi:78 */
			maximum-speed = "full-speed";     /* in Engineer-sdk/zephyr/dts/arm/st/h7/stm32h723.dtsi:79 */
			clocks = < &rcc 0xd8 0x2000000 >,
			         < &rcc 0x5 0x18d40054 >; /* in Engineer-sdk/zephyr/dts/arm/st/h7/stm32h723.dtsi:80 */
			phys = < &otghs_fs_phy >;         /* in Engineer-sdk/zephyr/dts/arm/st/h7/stm32h723.dtsi:82 */
			status = "disabled";              /* in Engineer-sdk/zephyr/dts/arm/st/h7/stm32h723.dtsi:83 */
		};

		/* node '/soc/display-controller@50001000' defined in Engineer-sdk/zephyr/dts/arm/st/h7/stm32h723.dtsi:86 */
		ltdc: display-controller@50001000 {
			compatible = "st,stm32-ltdc"; /* in Engineer-sdk/zephyr/dts/arm/st/h7/stm32h723.dtsi:87 */
			reg = < 0x50001000 0x200 >;   /* in Engineer-sdk/zephyr/dts/arm/st/h7/stm32h723.dtsi:88 */
			interrupts = < 0x58 0x0 >,
			             < 0x59 0x0 >;    /* in Engineer-sdk/zephyr/dts/arm/st/h7/stm32h723.dtsi:89 */
			interrupt-names = "ltdc",
			                  "ltdc_er";  /* in Engineer-sdk/zephyr/dts/arm/st/h7/stm32h723.dtsi:90 */
			clocks = < &rcc 0xe4 0x8 >;   /* in Engineer-sdk/zephyr/dts/arm/st/h7/stm32h723.dtsi:91 */
			resets = < &rctl 0x1183 >;    /* in Engineer-sdk/zephyr/dts/arm/st/h7/stm32h723.dtsi:92 */
			status = "disabled";          /* in Engineer-sdk/zephyr/dts/arm/st/h7/stm32h723.dtsi:93 */
		};

		/* node '/soc/spi@5200a000' defined in Engineer-sdk/zephyr/dts/arm/st/h7/stm32h723.dtsi:108 */
		octospi2: spi@5200a000 {
			compatible = "st,stm32-ospi";    /* in Engineer-sdk/zephyr/dts/arm/st/h7/stm32h723.dtsi:109 */
			reg = < 0x5200a000 0x1000 >,
			      < 0x70000000 0x10000000 >; /* in Engineer-sdk/zephyr/dts/arm/st/h7/stm32h723.dtsi:110 */
			interrupts = < 0x96 0x0 >;       /* in Engineer-sdk/zephyr/dts/arm/st/h7/stm32h723.dtsi:111 */
			clock-names = "ospix",
			              "ospi-ker";        /* in Engineer-sdk/zephyr/dts/arm/st/h7/stm32h723.dtsi:112 */
			clocks = < &rcc 0xd4 0x80000 >,
			         < &rcc 0x9 0x8c4004c >; /* in Engineer-sdk/zephyr/dts/arm/st/h7/stm32h723.dtsi:113 */
			#address-cells = < 0x1 >;        /* in Engineer-sdk/zephyr/dts/arm/st/h7/stm32h723.dtsi:115 */
			#size-cells = < 0x0 >;           /* in Engineer-sdk/zephyr/dts/arm/st/h7/stm32h723.dtsi:116 */
			status = "disabled";             /* in Engineer-sdk/zephyr/dts/arm/st/h7/stm32h723.dtsi:117 */
		};

		/* node '/soc/can@4000d400' defined in Engineer-sdk/zephyr/dts/arm/st/h7/stm32h723.dtsi:120 */
		fdcan3: can@4000d400 {
			compatible = "st,stm32h7-fdcan";                       /* in Engineer-sdk/zephyr/dts/arm/st/h7/stm32h723.dtsi:121 */
			reg = < 0x4000d400 0x400 >,
			      < 0x4000ac00 0x9f0 >;                            /* in Engineer-sdk/zephyr/dts/arm/st/h7/stm32h723.dtsi:122 */
			reg-names = "m_can",
			            "message_ram";                             /* in Engineer-sdk/zephyr/dts/arm/st/h7/stm32h723.dtsi:123 */
			interrupts = < 0x9f 0x0 >,
			             < 0xa0 0x0 >,
			             < 0x3f 0x0 >;                             /* in Engineer-sdk/zephyr/dts/arm/st/h7/stm32h723.dtsi:125 */
			interrupt-names = "int0",
			                  "int1",
			                  "calib";                             /* in Engineer-sdk/zephyr/dts/arm/st/h7/stm32h723.dtsi:126 */
			status = "okay";                                       /* in Engineer-manifest/boards/damiao/mc02/damiao_mc02.dts:334 */
			bosch,mram-cfg = < 0x0 0x1c 0x8 0x3 0x3 0x0 0x3 0x3 >; /* in Engineer-manifest/boards/damiao/mc02/damiao_mc02.dts:335 */
			clocks = < &rcc 0xec 0x100 >,
			         < &rcc 0xc 0x10dc0050 >;                      /* in Engineer-manifest/boards/damiao/mc02/damiao_mc02.dts:336 */
			pinctrl-0 = < &fdcan3_rx_pd12 &fdcan3_tx_pd13 >;       /* in Engineer-manifest/boards/damiao/mc02/damiao_mc02.dts:338 */
			pinctrl-names = "default";                             /* in Engineer-manifest/boards/damiao/mc02/damiao_mc02.dts:339 */
		};

		/* node '/soc/timers@4000e000' defined in Engineer-sdk/zephyr/dts/arm/st/h7/stm32h723.dtsi:139 */
		timers23: timers@4000e000 {
			compatible = "st,stm32-timers";   /* in Engineer-sdk/zephyr/dts/arm/st/h7/stm32h723.dtsi:140 */
			reg = < 0x4000e000 0x400 >;       /* in Engineer-sdk/zephyr/dts/arm/st/h7/stm32h723.dtsi:141 */
			clocks = < &rcc 0xec 0x1000000 >,
			         < &rcc 0x12 0xff >;      /* in Engineer-sdk/zephyr/dts/arm/st/h7/stm32h723.dtsi:142 */
			resets = < &rctl 0x1298 >;        /* in Engineer-sdk/zephyr/dts/arm/st/h7/stm32h723.dtsi:144 */
			interrupts = < 0xa1 0x0 >;        /* in Engineer-sdk/zephyr/dts/arm/st/h7/stm32h723.dtsi:145 */
			interrupt-names = "global";       /* in Engineer-sdk/zephyr/dts/arm/st/h7/stm32h723.dtsi:146 */
			st,prescaler = < 0x0 >;           /* in Engineer-sdk/zephyr/dts/arm/st/h7/stm32h723.dtsi:147 */
			status = "disabled";              /* in Engineer-sdk/zephyr/dts/arm/st/h7/stm32h723.dtsi:148 */

			/* node '/soc/timers@4000e000/pwm' defined in Engineer-sdk/zephyr/dts/arm/st/h7/stm32h723.dtsi:150 */
			pwm {
				compatible = "st,stm32-pwm"; /* in Engineer-sdk/zephyr/dts/arm/st/h7/stm32h723.dtsi:151 */
				status = "disabled";         /* in Engineer-sdk/zephyr/dts/arm/st/h7/stm32h723.dtsi:152 */
				#pwm-cells = < 0x3 >;        /* in Engineer-sdk/zephyr/dts/arm/st/h7/stm32h723.dtsi:153 */
			};

			/* node '/soc/timers@4000e000/counter' defined in Engineer-sdk/zephyr/dts/arm/st/h7/stm32h723.dtsi:156 */
			counter {
				compatible = "st,stm32-counter"; /* in Engineer-sdk/zephyr/dts/arm/st/h7/stm32h723.dtsi:157 */
				status = "disabled";             /* in Engineer-sdk/zephyr/dts/arm/st/h7/stm32h723.dtsi:158 */
			};
		};

		/* node '/soc/timers@4000e400' defined in Engineer-sdk/zephyr/dts/arm/st/h7/stm32h723.dtsi:162 */
		timers24: timers@4000e400 {
			compatible = "st,stm32-timers";   /* in Engineer-sdk/zephyr/dts/arm/st/h7/stm32h723.dtsi:163 */
			reg = < 0x4000e400 0x400 >;       /* in Engineer-sdk/zephyr/dts/arm/st/h7/stm32h723.dtsi:164 */
			clocks = < &rcc 0xec 0x2000000 >,
			         < &rcc 0x12 0xff >;      /* in Engineer-sdk/zephyr/dts/arm/st/h7/stm32h723.dtsi:165 */
			resets = < &rctl 0x1299 >;        /* in Engineer-sdk/zephyr/dts/arm/st/h7/stm32h723.dtsi:167 */
			interrupts = < 0xa2 0x0 >;        /* in Engineer-sdk/zephyr/dts/arm/st/h7/stm32h723.dtsi:168 */
			interrupt-names = "global";       /* in Engineer-sdk/zephyr/dts/arm/st/h7/stm32h723.dtsi:169 */
			st,prescaler = < 0x0 >;           /* in Engineer-sdk/zephyr/dts/arm/st/h7/stm32h723.dtsi:170 */
			status = "disabled";              /* in Engineer-sdk/zephyr/dts/arm/st/h7/stm32h723.dtsi:171 */

			/* node '/soc/timers@4000e400/pwm' defined in Engineer-sdk/zephyr/dts/arm/st/h7/stm32h723.dtsi:173 */
			pwm {
				compatible = "st,stm32-pwm"; /* in Engineer-sdk/zephyr/dts/arm/st/h7/stm32h723.dtsi:174 */
				status = "disabled";         /* in Engineer-sdk/zephyr/dts/arm/st/h7/stm32h723.dtsi:175 */
				#pwm-cells = < 0x3 >;        /* in Engineer-sdk/zephyr/dts/arm/st/h7/stm32h723.dtsi:176 */
			};

			/* node '/soc/timers@4000e400/counter' defined in Engineer-sdk/zephyr/dts/arm/st/h7/stm32h723.dtsi:179 */
			counter {
				compatible = "st,stm32-counter"; /* in Engineer-sdk/zephyr/dts/arm/st/h7/stm32h723.dtsi:180 */
				status = "disabled";             /* in Engineer-sdk/zephyr/dts/arm/st/h7/stm32h723.dtsi:181 */
			};
		};

		/* node '/soc/digi_dietemp@58006800' defined in Engineer-sdk/zephyr/dts/arm/st/h7/stm32h723.dtsi:185 */
		digi_die_temp: digi_dietemp@58006800 {
			compatible = "st,stm32-digi-temp"; /* in Engineer-sdk/zephyr/dts/arm/st/h7/stm32h723.dtsi:186 */
			reg = < 0x58006800 0x400 >;        /* in Engineer-sdk/zephyr/dts/arm/st/h7/stm32h723.dtsi:187 */
			interrupts = < 0x93 0x0 >;         /* in Engineer-sdk/zephyr/dts/arm/st/h7/stm32h723.dtsi:188 */
			interrupt-names = "digi_temp";     /* in Engineer-sdk/zephyr/dts/arm/st/h7/stm32h723.dtsi:189 */
			clocks = < &rcc 0xf4 0x4000000 >;  /* in Engineer-sdk/zephyr/dts/arm/st/h7/stm32h723.dtsi:190 */
			status = "okay";                   /* in Engineer-manifest/boards/damiao/mc02/damiao_mc02.dts:137 */
		};
	};

	/* node '/cpus' defined in Engineer-sdk/zephyr/dts/arm/st/h7/stm32h7.dtsi:32 */
	cpus {
		#address-cells = < 0x1 >; /* in Engineer-sdk/zephyr/dts/arm/st/h7/stm32h7.dtsi:33 */
		#size-cells = < 0x0 >;    /* in Engineer-sdk/zephyr/dts/arm/st/h7/stm32h7.dtsi:34 */

		/* node '/cpus/cpu@0' defined in Engineer-sdk/zephyr/dts/arm/st/h7/stm32h7.dtsi:36 */
		cpu0: cpu@0 {
			device_type = "cpu";          /* in Engineer-sdk/zephyr/dts/arm/st/h7/stm32h7.dtsi:37 */
			compatible = "arm,cortex-m7"; /* in Engineer-sdk/zephyr/dts/arm/st/h7/stm32h7.dtsi:38 */
			reg = < 0x0 >;                /* in Engineer-sdk/zephyr/dts/arm/st/h7/stm32h7.dtsi:39 */
			#address-cells = < 0x1 >;     /* in Engineer-sdk/zephyr/dts/arm/st/h7/stm32h7.dtsi:40 */
			#size-cells = < 0x1 >;        /* in Engineer-sdk/zephyr/dts/arm/st/h7/stm32h7.dtsi:41 */

			/* node '/cpus/cpu@0/mpu@e000ed90' defined in Engineer-sdk/zephyr/dts/arm/st/h7/stm32h7.dtsi:43 */
			mpu: mpu@e000ed90 {
				compatible = "arm,armv7m-mpu"; /* in Engineer-sdk/zephyr/dts/arm/st/h7/stm32h7.dtsi:44 */
				reg = < 0xe000ed90 0x40 >;     /* in Engineer-sdk/zephyr/dts/arm/st/h7/stm32h7.dtsi:45 */
			};
		};
	};

	/* node '/memory@90000000' defined in Engineer-sdk/zephyr/dts/arm/st/h7/stm32h7.dtsi:50 */
	ext_memory: memory@90000000 {
		compatible = "zephyr,memory-region"; /* in Engineer-sdk/zephyr/dts/arm/st/h7/stm32h7.dtsi:51 */
		reg = < 0x90000000 0x10000000 >;     /* in Engineer-sdk/zephyr/dts/arm/st/h7/stm32h7.dtsi:52 */
		zephyr,memory-region = "EXTMEM";     /* in Engineer-sdk/zephyr/dts/arm/st/h7/stm32h7.dtsi:53 */
		zephyr,memory-attr = < 0x2000000 >;  /* in Engineer-sdk/zephyr/dts/arm/st/h7/stm32h7.dtsi:54 */
	};

	/* node '/clocks' defined in Engineer-sdk/zephyr/dts/arm/st/h7/stm32h7.dtsi:57 */
	clocks {
		#address-cells = < 0x1 >; /* in Engineer-sdk/zephyr/dts/arm/st/h7/stm32h7.dtsi:58 */
		#size-cells = < 0x0 >;    /* in Engineer-sdk/zephyr/dts/arm/st/h7/stm32h7.dtsi:59 */

		/* node '/clocks/clk-hse' defined in Engineer-sdk/zephyr/dts/arm/st/h7/stm32h7.dtsi:61 */
		clk_hse: clk-hse {
			#clock-cells = < 0x0 >;            /* in Engineer-sdk/zephyr/dts/arm/st/h7/stm32h7.dtsi:62 */
			compatible = "st,stm32-hse-clock"; /* in Engineer-sdk/zephyr/dts/arm/st/h7/stm32h7.dtsi:63 */
			clock-frequency = < 0x16e3600 >;   /* in Engineer-manifest/boards/damiao/mc02/damiao_mc02.dts:60 */
			status = "okay";                   /* in Engineer-manifest/boards/damiao/mc02/damiao_mc02.dts:61 */
			phandle = < 0x24 >;                /* in Engineer-manifest/boards/damiao/mc02/damiao_mc02.dts:66 */
		};

		/* node '/clocks/clk-hsi' defined in Engineer-sdk/zephyr/dts/arm/st/h7/stm32h7.dtsi:67 */
		clk_hsi: clk-hsi {
			#clock-cells = < 0x0 >;              /* in Engineer-sdk/zephyr/dts/arm/st/h7/stm32h7.dtsi:68 */
			compatible = "st,stm32h7-hsi-clock"; /* in Engineer-sdk/zephyr/dts/arm/st/h7/stm32h7.dtsi:69 */
			hsi-div = < 0x1 >;                   /* in Engineer-sdk/zephyr/dts/arm/st/h7/stm32h7.dtsi:70 */
			clock-frequency = < 0x3d09000 >;     /* in Engineer-sdk/zephyr/dts/arm/st/h7/stm32h7.dtsi:71 */
			status = "disabled";                 /* in Engineer-sdk/zephyr/dts/arm/st/h7/stm32h7.dtsi:72 */
		};

		/* node '/clocks/clk-hsi48' defined in Engineer-sdk/zephyr/dts/arm/st/h7/stm32h7.dtsi:75 */
		clk_hsi48: clk-hsi48 {
			#clock-cells = < 0x0 >;          /* in Engineer-sdk/zephyr/dts/arm/st/h7/stm32h7.dtsi:76 */
			compatible = "fixed-clock";      /* in Engineer-sdk/zephyr/dts/arm/st/h7/stm32h7.dtsi:77 */
			clock-frequency = < 0x2dc6c00 >; /* in Engineer-sdk/zephyr/dts/arm/st/h7/stm32h7.dtsi:78 */
			status = "okay";                 /* in Engineer-manifest/boards/damiao/mc02/damiao_mc02.dts:55 */
		};

		/* node '/clocks/clk-csi' defined in Engineer-sdk/zephyr/dts/arm/st/h7/stm32h7.dtsi:82 */
		clk_csi: clk-csi {
			#clock-cells = < 0x0 >;         /* in Engineer-sdk/zephyr/dts/arm/st/h7/stm32h7.dtsi:83 */
			compatible = "fixed-clock";     /* in Engineer-sdk/zephyr/dts/arm/st/h7/stm32h7.dtsi:84 */
			clock-frequency = < 0x3d0900 >; /* in Engineer-sdk/zephyr/dts/arm/st/h7/stm32h7.dtsi:85 */
			status = "disabled";            /* in Engineer-sdk/zephyr/dts/arm/st/h7/stm32h7.dtsi:86 */
		};

		/* node '/clocks/clk-lse' defined in Engineer-sdk/zephyr/dts/arm/st/h7/stm32h7.dtsi:89 */
		clk_lse: clk-lse {
			#clock-cells = < 0x0 >;            /* in Engineer-sdk/zephyr/dts/arm/st/h7/stm32h7.dtsi:90 */
			compatible = "st,stm32-lse-clock"; /* in Engineer-sdk/zephyr/dts/arm/st/h7/stm32h7.dtsi:91 */
			clock-frequency = < 0x8000 >;      /* in Engineer-sdk/zephyr/dts/arm/st/h7/stm32h7.dtsi:92 */
			driving-capability = < 0x0 >;      /* in Engineer-sdk/zephyr/dts/arm/st/h7/stm32h7.dtsi:93 */
			status = "disabled";               /* in Engineer-sdk/zephyr/dts/arm/st/h7/stm32h7.dtsi:94 */
		};

		/* node '/clocks/clk-lsi' defined in Engineer-sdk/zephyr/dts/arm/st/h7/stm32h7.dtsi:97 */
		clk_lsi: clk-lsi {
			#clock-cells = < 0x0 >;       /* in Engineer-sdk/zephyr/dts/arm/st/h7/stm32h7.dtsi:98 */
			compatible = "fixed-clock";   /* in Engineer-sdk/zephyr/dts/arm/st/h7/stm32h7.dtsi:99 */
			clock-frequency = < 0x7d00 >; /* in Engineer-sdk/zephyr/dts/arm/st/h7/stm32h7.dtsi:100 */
			status = "okay";              /* in Engineer-manifest/boards/damiao/mc02/damiao_mc02.dts:51 */
		};

		/* node '/clocks/pll@0' defined in Engineer-sdk/zephyr/dts/arm/st/h7/stm32h7.dtsi:104 */
		pll: pll@0 {
			#clock-cells = < 0x0 >;              /* in Engineer-sdk/zephyr/dts/arm/st/h7/stm32h7.dtsi:105 */
			compatible = "st,stm32h7-pll-clock"; /* in Engineer-sdk/zephyr/dts/arm/st/h7/stm32h7.dtsi:106 */
			reg = < 0x0 >;                       /* in Engineer-sdk/zephyr/dts/arm/st/h7/stm32h7.dtsi:107 */
			clocks = < &clk_hse >;               /* in Engineer-manifest/boards/damiao/mc02/damiao_mc02.dts:66 */
			div-m = < 0xc >;                     /* in Engineer-manifest/boards/damiao/mc02/damiao_mc02.dts:67 */
			mul-n = < 0x113 >;                   /* in Engineer-manifest/boards/damiao/mc02/damiao_mc02.dts:68 */
			div-p = < 0x1 >;                     /* in Engineer-manifest/boards/damiao/mc02/damiao_mc02.dts:69 */
			div-q = < 0x2 >;                     /* in Engineer-manifest/boards/damiao/mc02/damiao_mc02.dts:70 */
			div-r = < 0x2 >;                     /* in Engineer-manifest/boards/damiao/mc02/damiao_mc02.dts:71 */
			status = "okay";                     /* in Engineer-manifest/boards/damiao/mc02/damiao_mc02.dts:72 */
			phandle = < 0x2 >;                   /* in Engineer-manifest/boards/damiao/mc02/damiao_mc02.dts:96 */
		};

		/* node '/clocks/pll@1' defined in Engineer-sdk/zephyr/dts/arm/st/h7/stm32h7.dtsi:111 */
		pll2: pll@1 {
			#clock-cells = < 0x0 >;              /* in Engineer-sdk/zephyr/dts/arm/st/h7/stm32h7.dtsi:112 */
			compatible = "st,stm32h7-pll-clock"; /* in Engineer-sdk/zephyr/dts/arm/st/h7/stm32h7.dtsi:113 */
			reg = < 0x1 >;                       /* in Engineer-sdk/zephyr/dts/arm/st/h7/stm32h7.dtsi:114 */
			clocks = < &clk_hse >;               /* in Engineer-manifest/boards/damiao/mc02/damiao_mc02.dts:76 */
			div-m = < 0x2 >;                     /* in Engineer-manifest/boards/damiao/mc02/damiao_mc02.dts:77 */
			mul-n = < 0x28 >;                    /* in Engineer-manifest/boards/damiao/mc02/damiao_mc02.dts:78 */
			div-p = < 0x4 >;                     /* in Engineer-manifest/boards/damiao/mc02/damiao_mc02.dts:79 */
			div-q = < 0x4 >;                     /* in Engineer-manifest/boards/damiao/mc02/damiao_mc02.dts:80 */
			div-r = < 0x2 >;                     /* in Engineer-manifest/boards/damiao/mc02/damiao_mc02.dts:81 */
			status = "okay";                     /* in Engineer-manifest/boards/damiao/mc02/damiao_mc02.dts:82 */
		};

		/* node '/clocks/pll@2' defined in Engineer-sdk/zephyr/dts/arm/st/h7/stm32h7.dtsi:118 */
		pll3: pll@2 {
			#clock-cells = < 0x0 >;              /* in Engineer-sdk/zephyr/dts/arm/st/h7/stm32h7.dtsi:119 */
			compatible = "st,stm32h7-pll-clock"; /* in Engineer-sdk/zephyr/dts/arm/st/h7/stm32h7.dtsi:120 */
			reg = < 0x2 >;                       /* in Engineer-sdk/zephyr/dts/arm/st/h7/stm32h7.dtsi:121 */
			clocks = < &clk_hse >;               /* in Engineer-manifest/boards/damiao/mc02/damiao_mc02.dts:86 */
			div-m = < 0x2 >;                     /* in Engineer-manifest/boards/damiao/mc02/damiao_mc02.dts:87 */
			mul-n = < 0x10 >;                    /* in Engineer-manifest/boards/damiao/mc02/damiao_mc02.dts:88 */
			div-p = < 0x2 >;                     /* in Engineer-manifest/boards/damiao/mc02/damiao_mc02.dts:89 */
			div-q = < 0x4 >;                     /* in Engineer-manifest/boards/damiao/mc02/damiao_mc02.dts:90 */
			div-r = < 0x2 >;                     /* in Engineer-manifest/boards/damiao/mc02/damiao_mc02.dts:91 */
			status = "okay";                     /* in Engineer-manifest/boards/damiao/mc02/damiao_mc02.dts:92 */
		};

		/* node '/clocks/perck' defined in Engineer-sdk/zephyr/dts/arm/st/h7/stm32h7.dtsi:125 */
		perck: perck {
			#clock-cells = < 0x0 >;            /* in Engineer-sdk/zephyr/dts/arm/st/h7/stm32h7.dtsi:126 */
			compatible = "st,stm32-clock-mux"; /* in Engineer-sdk/zephyr/dts/arm/st/h7/stm32h7.dtsi:127 */
			status = "disabled";               /* in Engineer-sdk/zephyr/dts/arm/st/h7/stm32h7.dtsi:128 */
		};
	};

	/* node '/mcos' defined in Engineer-sdk/zephyr/dts/arm/st/h7/stm32h7.dtsi:132 */
	mcos {

		/* node '/mcos/mco1' defined in Engineer-sdk/zephyr/dts/arm/st/h7/stm32h7.dtsi:133 */
		mco1: mco1 {
			compatible = "st,stm32-clock-mco"; /* in Engineer-sdk/zephyr/dts/arm/st/h7/stm32h7.dtsi:134 */
			status = "disabled";               /* in Engineer-sdk/zephyr/dts/arm/st/h7/stm32h7.dtsi:135 */
		};

		/* node '/mcos/mco2' defined in Engineer-sdk/zephyr/dts/arm/st/h7/stm32h7.dtsi:138 */
		mco2: mco2 {
			compatible = "st,stm32-clock-mco"; /* in Engineer-sdk/zephyr/dts/arm/st/h7/stm32h7.dtsi:139 */
			status = "disabled";               /* in Engineer-sdk/zephyr/dts/arm/st/h7/stm32h7.dtsi:140 */
		};
	};

	/* node '/dietemp' defined in Engineer-sdk/zephyr/dts/arm/st/h7/stm32h7.dtsi:1136 */
	die_temp: dietemp {
		compatible = "st,stm32-temp-cal"; /* in Engineer-sdk/zephyr/dts/arm/st/h7/stm32h7.dtsi:1137 */
		ts-cal1-addr = < 0x1ff1e820 >;    /* in Engineer-sdk/zephyr/dts/arm/st/h7/stm32h7.dtsi:1138 */
		ts-cal2-addr = < 0x1ff1e840 >;    /* in Engineer-sdk/zephyr/dts/arm/st/h7/stm32h7.dtsi:1139 */
		ts-cal1-temp = < 0x1e >;          /* in Engineer-sdk/zephyr/dts/arm/st/h7/stm32h7.dtsi:1140 */
		ts-cal-vrefanalog = < 0xce4 >;    /* in Engineer-sdk/zephyr/dts/arm/st/h7/stm32h7.dtsi:1142 */
		ts-cal-resolution = < 0x10 >;     /* in Engineer-sdk/zephyr/dts/arm/st/h7/stm32h7.dtsi:1143 */
		status = "disabled";              /* in Engineer-sdk/zephyr/dts/arm/st/h7/stm32h7.dtsi:1145 */
		io-channels = < &adc3 0x11 >;     /* in Engineer-sdk/zephyr/dts/arm/st/h7/stm32h723.dtsi:242 */
		ts-cal2-temp = < 0x82 >;          /* in Engineer-sdk/zephyr/dts/arm/st/h7/stm32h723.dtsi:243 */
	};

	/* node '/vbat' defined in Engineer-sdk/zephyr/dts/arm/st/h7/stm32h7.dtsi:1148 */
	vbat: vbat {
		compatible = "st,stm32-vbat"; /* in Engineer-sdk/zephyr/dts/arm/st/h7/stm32h7.dtsi:1149 */
		ratio = < 0x4 >;              /* in Engineer-sdk/zephyr/dts/arm/st/h7/stm32h7.dtsi:1150 */
		status = "disabled";          /* in Engineer-sdk/zephyr/dts/arm/st/h7/stm32h7.dtsi:1151 */
		io-channels = < &adc3 0x10 >; /* in Engineer-sdk/zephyr/dts/arm/st/h7/stm32h723.dtsi:251 */
	};

	/* node '/vref' defined in Engineer-sdk/zephyr/dts/arm/st/h7/stm32h7.dtsi:1154 */
	vref: vref {
		compatible = "st,stm32-vref";      /* in Engineer-sdk/zephyr/dts/arm/st/h7/stm32h7.dtsi:1155 */
		vrefint-cal-addr = < 0x1ff1e860 >; /* in Engineer-sdk/zephyr/dts/arm/st/h7/stm32h7.dtsi:1156 */
		vrefint-cal-mv = < 0xce4 >;        /* in Engineer-sdk/zephyr/dts/arm/st/h7/stm32h7.dtsi:1157 */
		vrefint-cal-resolution = < 0x10 >; /* in Engineer-sdk/zephyr/dts/arm/st/h7/stm32h7.dtsi:1158 */
		status = "disabled";               /* in Engineer-sdk/zephyr/dts/arm/st/h7/stm32h7.dtsi:1159 */
		io-channels = < &adc3 0x12 >;      /* in Engineer-sdk/zephyr/dts/arm/st/h7/stm32h723.dtsi:247 */
	};

	/* node '/smbus1' defined in Engineer-sdk/zephyr/dts/arm/st/h7/stm32h7.dtsi:1162 */
	smbus1: smbus1 {
		compatible = "st,stm32-smbus"; /* in Engineer-sdk/zephyr/dts/arm/st/h7/stm32h7.dtsi:1163 */
		#address-cells = < 0x1 >;      /* in Engineer-sdk/zephyr/dts/arm/st/h7/stm32h7.dtsi:1164 */
		#size-cells = < 0x0 >;         /* in Engineer-sdk/zephyr/dts/arm/st/h7/stm32h7.dtsi:1165 */
		i2c = < &i2c1 >;               /* in Engineer-sdk/zephyr/dts/arm/st/h7/stm32h7.dtsi:1166 */
		status = "disabled";           /* in Engineer-sdk/zephyr/dts/arm/st/h7/stm32h7.dtsi:1167 */
	};

	/* node '/smbus2' defined in Engineer-sdk/zephyr/dts/arm/st/h7/stm32h7.dtsi:1170 */
	smbus2: smbus2 {
		compatible = "st,stm32-smbus"; /* in Engineer-sdk/zephyr/dts/arm/st/h7/stm32h7.dtsi:1171 */
		#address-cells = < 0x1 >;      /* in Engineer-sdk/zephyr/dts/arm/st/h7/stm32h7.dtsi:1172 */
		#size-cells = < 0x0 >;         /* in Engineer-sdk/zephyr/dts/arm/st/h7/stm32h7.dtsi:1173 */
		i2c = < &i2c2 >;               /* in Engineer-sdk/zephyr/dts/arm/st/h7/stm32h7.dtsi:1174 */
		status = "disabled";           /* in Engineer-sdk/zephyr/dts/arm/st/h7/stm32h7.dtsi:1175 */
	};

	/* node '/smbus3' defined in Engineer-sdk/zephyr/dts/arm/st/h7/stm32h7.dtsi:1178 */
	smbus3: smbus3 {
		compatible = "st,stm32-smbus"; /* in Engineer-sdk/zephyr/dts/arm/st/h7/stm32h7.dtsi:1179 */
		#address-cells = < 0x1 >;      /* in Engineer-sdk/zephyr/dts/arm/st/h7/stm32h7.dtsi:1180 */
		#size-cells = < 0x0 >;         /* in Engineer-sdk/zephyr/dts/arm/st/h7/stm32h7.dtsi:1181 */
		i2c = < &i2c3 >;               /* in Engineer-sdk/zephyr/dts/arm/st/h7/stm32h7.dtsi:1182 */
		status = "disabled";           /* in Engineer-sdk/zephyr/dts/arm/st/h7/stm32h7.dtsi:1183 */
	};

	/* node '/smbus4' defined in Engineer-sdk/zephyr/dts/arm/st/h7/stm32h7.dtsi:1186 */
	smbus4: smbus4 {
		compatible = "st,stm32-smbus"; /* in Engineer-sdk/zephyr/dts/arm/st/h7/stm32h7.dtsi:1187 */
		#address-cells = < 0x1 >;      /* in Engineer-sdk/zephyr/dts/arm/st/h7/stm32h7.dtsi:1188 */
		#size-cells = < 0x0 >;         /* in Engineer-sdk/zephyr/dts/arm/st/h7/stm32h7.dtsi:1189 */
		i2c = < &i2c4 >;               /* in Engineer-sdk/zephyr/dts/arm/st/h7/stm32h7.dtsi:1190 */
		status = "disabled";           /* in Engineer-sdk/zephyr/dts/arm/st/h7/stm32h7.dtsi:1191 */
	};

	/* node '/memory@24000000' defined in Engineer-sdk/zephyr/dts/arm/st/h7/stm32h723.dtsi:196 */
	sram0: memory@24000000 {
		reg = < 0x24000000 0x50000 >; /* in Engineer-sdk/zephyr/dts/arm/st/h7/stm32h723.dtsi:197 */
		compatible = "mmio-sram";     /* in Engineer-sdk/zephyr/dts/arm/st/h7/stm32h723.dtsi:198 */
	};

	/* node '/memory@30000000' defined in Engineer-sdk/zephyr/dts/arm/st/h7/stm32h723.dtsi:202 */
	sram1: memory@30000000 {
		reg = < 0x30000000 0x4000 >;         /* in Engineer-sdk/zephyr/dts/arm/st/h7/stm32h723.dtsi:203 */
		compatible = "zephyr,memory-region",
		             "mmio-sram";            /* in Engineer-sdk/zephyr/dts/arm/st/h7/stm32h723.dtsi:204 */
		zephyr,memory-region = "SRAM1";      /* in Engineer-sdk/zephyr/dts/arm/st/h7/stm32h723.dtsi:205 */
	};

	/* node '/memory@30004000' defined in Engineer-sdk/zephyr/dts/arm/st/h7/stm32h723.dtsi:209 */
	sram2: memory@30004000 {
		reg = < 0x30004000 0x4000 >;         /* in Engineer-sdk/zephyr/dts/arm/st/h7/stm32h723.dtsi:210 */
		compatible = "zephyr,memory-region",
		             "mmio-sram";            /* in Engineer-sdk/zephyr/dts/arm/st/h7/stm32h723.dtsi:211 */
		zephyr,memory-region = "SRAM2";      /* in Engineer-sdk/zephyr/dts/arm/st/h7/stm32h723.dtsi:212 */
	};

	/* node '/memory@38000000' defined in Engineer-sdk/zephyr/dts/arm/st/h7/stm32h723.dtsi:216 */
	sram4: memory@38000000 {
		reg = < 0x38000000 0x4000 >;         /* in Engineer-sdk/zephyr/dts/arm/st/h7/stm32h723.dtsi:217 */
		compatible = "zephyr,memory-region",
		             "mmio-sram";            /* in Engineer-sdk/zephyr/dts/arm/st/h7/stm32h723.dtsi:218 */
		zephyr,memory-region = "SRAM4";      /* in Engineer-sdk/zephyr/dts/arm/st/h7/stm32h723.dtsi:219 */
	};

	/* node '/memory@20000000' defined in Engineer-sdk/zephyr/dts/arm/st/h7/stm32h723.dtsi:223 */
	dtcm: memory@20000000 {
		compatible = "zephyr,memory-region",
		             "arm,dtcm";             /* in Engineer-sdk/zephyr/dts/arm/st/h7/stm32h723.dtsi:224 */
		reg = < 0x20000000 0x20000 >;        /* in Engineer-sdk/zephyr/dts/arm/st/h7/stm32h723.dtsi:225 */
		zephyr,memory-region = "DTCM";       /* in Engineer-sdk/zephyr/dts/arm/st/h7/stm32h723.dtsi:226 */
	};

	/* node '/memory@0' defined in Engineer-sdk/zephyr/dts/arm/st/h7/stm32h723.dtsi:230 */
	itcm: memory@0 {
		compatible = "zephyr,memory-region",
		             "arm,itcm";             /* in Engineer-sdk/zephyr/dts/arm/st/h7/stm32h723.dtsi:231 */
		reg = < 0x0 0x10000 >;               /* in Engineer-sdk/zephyr/dts/arm/st/h7/stm32h723.dtsi:232 */
		zephyr,memory-region = "ITCM";       /* in Engineer-sdk/zephyr/dts/arm/st/h7/stm32h723.dtsi:233 */
	};

	/* node '/otghs_fs_phy' defined in Engineer-sdk/zephyr/dts/arm/st/h7/stm32h723.dtsi:236 */
	otghs_fs_phy: otghs_fs_phy {
		compatible = "usb-nop-xceiv"; /* in Engineer-sdk/zephyr/dts/arm/st/h7/stm32h723.dtsi:237 */
		#phy-cells = < 0x0 >;         /* in Engineer-sdk/zephyr/dts/arm/st/h7/stm32h723.dtsi:238 */
		phandle = < 0x21 >;           /* in Engineer-sdk/zephyr/dts/arm/st/h7/stm32h723.dtsi:82 */
	};

	/* node '/gpio_keys' defined in Engineer-manifest/boards/damiao/mc02/damiao_mc02.dts:34 */
	gpio_keys {
		compatible = "gpio-keys"; /* in Engineer-manifest/boards/damiao/mc02/damiao_mc02.dts:35 */

		/* node '/gpio_keys/button_0' defined in Engineer-manifest/boards/damiao/mc02/damiao_mc02.dts:36 */
		user_button: button_0 {
			gpios = < &gpioa 0xf 0x20 >; /* in Engineer-manifest/boards/damiao/mc02/damiao_mc02.dts:37 */
			label = "user";              /* in Engineer-manifest/boards/damiao/mc02/damiao_mc02.dts:38 */
			zephyr,code = < 0xb >;       /* in Engineer-manifest/boards/damiao/mc02/damiao_mc02.dts:39 */
		};
	};
};
